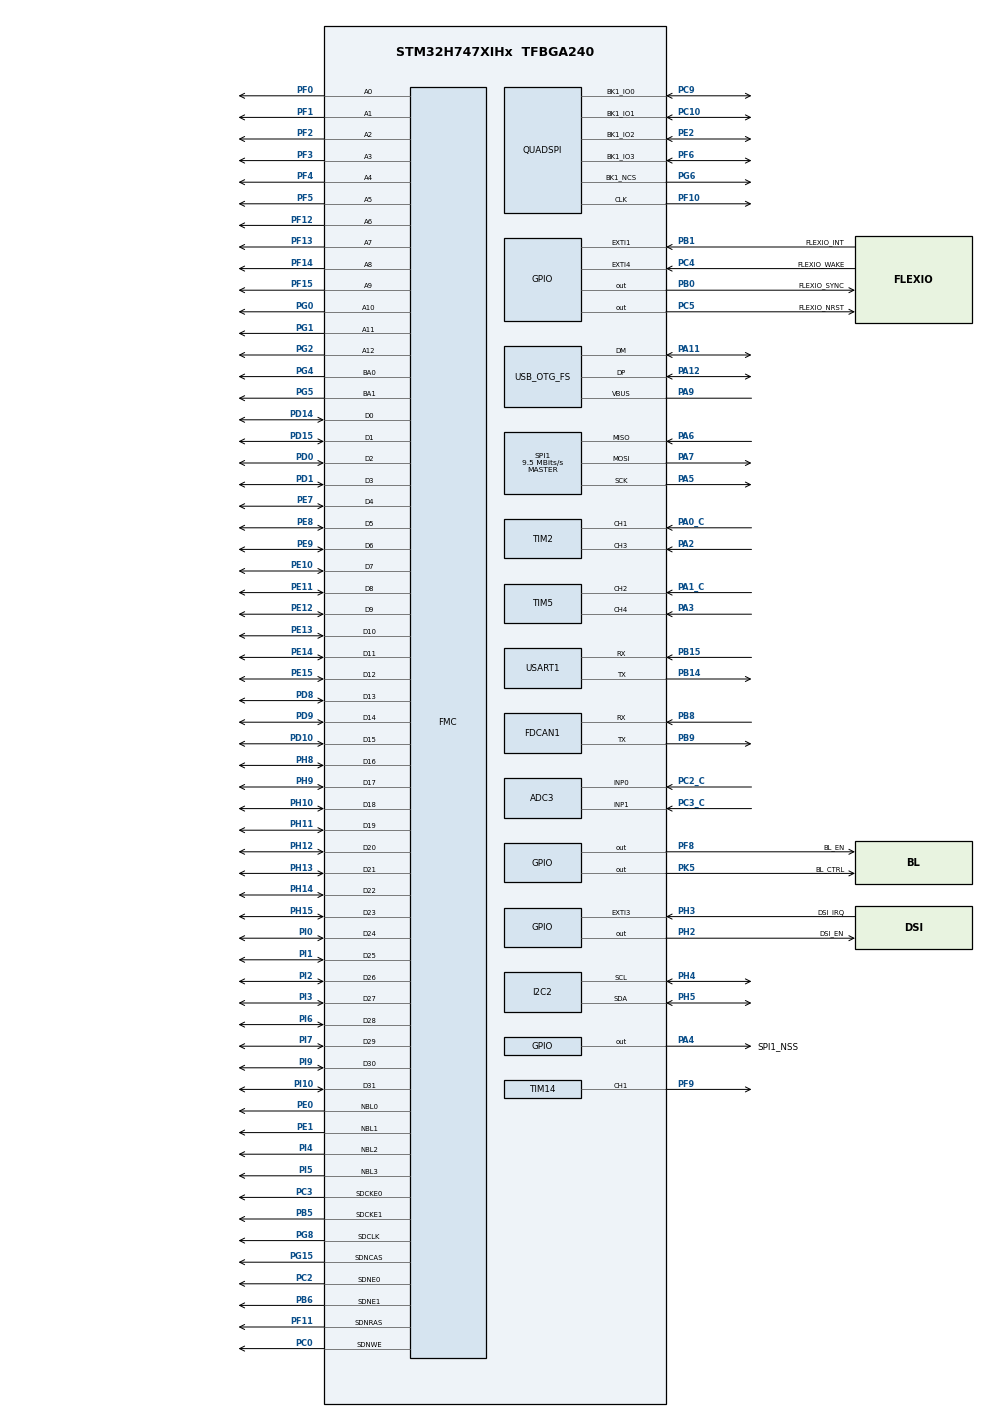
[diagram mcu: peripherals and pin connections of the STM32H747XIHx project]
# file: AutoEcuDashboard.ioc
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ADC3.AWD2FilteringConfig-Analog\ Watchdog\ 2=ADC3_AWD_FILTERING_NONE
ADC3.Channel-0\#ChannelRegularConversion=ADC_CHANNEL_0
ADC3.Channel-1\#ChannelRegularConversion=ADC_CHANNEL_1
ADC3.ContinuousConvMode=DISABLE
ADC3.EOCSelection=ADC_EOC_SEQ_CONV
ADC3.ExternalTrigConv=ADC_EXTERNALTRIG_T8_TRGO
ADC3.NbrOfConversion=2
ADC3.NbrOfConversionFlag=1
ADC3.OffsetNumber-0\#ChannelRegularConversion=ADC_OFFSET_NONE
ADC3.OffsetNumber-1\#ChannelRegularConversion=ADC_OFFSET_NONE
ADC3.OffsetSignedSaturation-0\#ChannelRegularConversion=DISABLE
ADC3.OffsetSignedSaturation-1\#ChannelRegularConversion=DISABLE
ADC3.Rank-0\#ChannelRegularConversion=1
ADC3.Rank-1\#ChannelRegularConversion=2
ADC3.SamplingTime-0\#ChannelRegularConversion=ADC_SAMPLETIME_64CYCLES_5
ADC3.SamplingTime-1\#ChannelRegularConversion=ADC_SAMPLETIME_64CYCLES_5
Bdma.ADC3.0.Direction=DMA_PERIPH_TO_MEMORY
Bdma.ADC3.0.EventEnable=DISABLE
Bdma.ADC3.0.Instance=BDMA_Channel0
Bdma.ADC3.0.MemDataAlignment=DMA_MDATAALIGN_HALFWORD
Bdma.ADC3.0.MemInc=DMA_MINC_ENABLE
Bdma.ADC3.0.Mode=DMA_CIRCULAR
Bdma.ADC3.0.PeriphDataAlignment=DMA_PDATAALIGN_HALFWORD
Bdma.ADC3.0.PeriphInc=DMA_PINC_DISABLE
Bdma.ADC3.0.Polarity=HAL_DMAMUX_REQ_GEN_RISING
Bdma.ADC3.0.Priority=DMA_PRIORITY_LOW
Bdma.ADC3.0.RequestNumber=1
Bdma.ADC3.0.SignalID=NONE
Bdma.ADC3.0.SyncEnable=DISABLE
Bdma.ADC3.0.SyncPolarity=HAL_DMAMUX_SYNC_NO_EVENT
Bdma.ADC3.0.SyncRequestNumber=1
Bdma.ADC3.0.SyncSignalID=NONE
Bdma.Request0=ADC3
Bdma.RequestsNb=1
CORTEX_M7.AccessPermission_Spec=MPU_REGION_PRIV_RW
CORTEX_M7.BaseAddress_Spec=0xC0000000
CORTEX_M7.CPU_DCache=Enabled
CORTEX_M7.CPU_ICache=Enabled
CORTEX_M7.DisableExec_Spec=MPU_INSTRUCTION_ACCESS_DISABLE
CORTEX_M7.Enable_Spec=MPU_REGION_ENABLE
CORTEX_M7.IsCacheable_Spec=MPU_ACCESS_CACHEABLE
CORTEX_M7.IsShareable_Spec=MPU_ACCESS_NOT_SHAREABLE
CORTEX_M7.Size_Spec=MPU_REGION_SIZE_64MB
CORTEX_M7.SubRegionDisable_Spec=0
CORTEX_M7.default_mode_Activation=1
CortexM4.IPs=CORTEX_M4\:I,FATFS_M4\:I,FREERTOS_M4\:I,IWDG2\:I,OPENAMP_M4\:I,PDM2PCM_M4\:I,PWR,RCC,RESMGR_UTILITY,SYS_M4\:I,USB_DEVICE_M4\:I,USB_HOST_M4\:I,VREFBUF,WWDG2\:I,GPIO,DMA,BDMA,MDMA,NVIC2\:I,DEBUG
CortexM7.IPs=CORTEX_M7\:I,FATFS_M7\:I,FREERTOS_M7\:I,IWDG1\:I,OPENAMP_M7\:I,PDM2PCM_M7\:I,PWR\:I,RCC\:I,RESMGR_UTILITY\:I,SYS\:I,USB_DEVICE_M7\:I,USB_HOST_M7\:I,VREFBUF\:I,WWDG1\:I,GPIO\:I,DMA\:I,BDMA\:I,MDMA\:I,NVIC1\:I,FMC\:I,DSIHOST\:I,LTDC\:I,CRC\:I,DMA2D\:I,JPEG\:I,DEBUG\:I,QUADSPI\:I,USB_OTG_FS\:I,USART1\:I,FDCAN1\:I,I2C2\:I,TIM2\:I,TIM5\:I,ADC3\:I,SPI1\:I,TIM14\:I,TIM8\:I,STMicroelectronics.X-CUBE-TOUCHGFX.4.25.0_M7\:I,TIM17\:I
CortexM7.Pins=PK5,PF8,PH2,PH3,PC4,PB1,PA4,PC5,PB0
DSIHOST.HorizontalBackPorch=148
DSIHOST.HorizontalLine=2200
DSIHOST.HorizontalSyncActive=44
DSIHOST.NumberOfLanes=DSI_TWO_DATA_LANES
DSI_CKN.Mode=DSIHost_Video
DSI_CKN.PinAttribute=CortexM7
DSI_CKN.Signal=DSIHOST_CKN
DSI_CKP.Mode=DSIHost_Video
DSI_CKP.PinAttribute=CortexM7
DSI_CKP.Signal=DSIHOST_CKP
DSI_D0N.Mode=DSIHost_Video
DSI_D0N.PinAttribute=CortexM7
DSI_D0N.Signal=DSIHOST_D0N
DSI_D0P.Mode=DSIHost_Video
DSI_D0P.PinAttribute=CortexM7
DSI_D0P.Signal=DSIHOST_D0P
DSI_D1N.Mode=DSIHost_Video
DSI_D1N.PinAttribute=CortexM7
DSI_D1N.Signal=DSIHOST_D1N
DSI_D1P.Mode=DSIHost_Video
DSI_D1P.PinAttribute=CortexM7
DSI_D1P.Signal=DSIHOST_D1P
Dma.Request0=SPI1_RX
Dma.Request1=SPI1_TX
Dma.Request2=USART1_RX
Dma.Request3=USART1_TX
Dma.SPI1_RX.0.Direction=DMA_PERIPH_TO_MEMORY
Dma.SPI1_RX.0.EventEnable=DISABLE
Dma.SPI1_RX.0.FIFOMode=DMA_FIFOMODE_DISABLE
Dma.SPI1_RX.0.Instance=DMA1_Stream0
Dma.SPI1_RX.0.MemDataAlignment=DMA_MDATAALIGN_BYTE
Dma.SPI1_RX.0.MemInc=DMA_MINC_ENABLE
Dma.SPI1_RX.0.Mode=DMA_NORMAL
Dma.SPI1_RX.0.PeriphDataAlignment=DMA_PDATAALIGN_BYTE
Dma.SPI1_RX.0.PeriphInc=DMA_PINC_DISABLE
Dma.SPI1_RX.0.Polarity=HAL_DMAMUX_REQ_GEN_RISING
Dma.SPI1_RX.0.Priority=DMA_PRIORITY_LOW
Dma.SPI1_RX.0.RequestNumber=1
Dma.SPI1_RX.0.SignalID=NONE
Dma.SPI1_RX.0.SyncEnable=DISABLE
Dma.SPI1_RX.0.SyncPolarity=HAL_DMAMUX_SYNC_NO_EVENT
Dma.SPI1_RX.0.SyncRequestNumber=1
Dma.SPI1_RX.0.SyncSignalID=NONE
Dma.SPI1_TX.1.Direction=DMA_MEMORY_TO_PERIPH
Dma.SPI1_TX.1.EventEnable=DISABLE
Dma.SPI1_TX.1.FIFOMode=DMA_FIFOMODE_DISABLE
Dma.SPI1_TX.1.Instance=DMA1_Stream1
Dma.SPI1_TX.1.MemDataAlignment=DMA_MDATAALIGN_BYTE
Dma.SPI1_TX.1.MemInc=DMA_MINC_ENABLE
Dma.SPI1_TX.1.Mode=DMA_NORMAL
Dma.SPI1_TX.1.PeriphDataAlignment=DMA_PDATAALIGN_BYTE
Dma.SPI1_TX.1.PeriphInc=DMA_PINC_DISABLE
Dma.SPI1_TX.1.Polarity=HAL_DMAMUX_REQ_GEN_RISING
Dma.SPI1_TX.1.Priority=DMA_PRIORITY_LOW
Dma.SPI1_TX.1.RequestNumber=1
Dma.SPI1_TX.1.SignalID=NONE
Dma.SPI1_TX.1.SyncEnable=DISABLE
Dma.SPI1_TX.1.SyncPolarity=HAL_DMAMUX_SYNC_NO_EVENT
Dma.SPI1_TX.1.SyncRequestNumber=1
Dma.SPI1_TX.1.SyncSignalID=NONE
Dma.USART1_RX.2.Direction=DMA_PERIPH_TO_MEMORY
Dma.USART1_RX.2.EventEnable=DISABLE
Dma.USART1_RX.2.FIFOMode=DMA_FIFOMODE_DISABLE
Dma.USART1_RX.2.Instance=DMA1_Stream2
Dma.USART1_RX.2.MemDataAlignment=DMA_MDATAALIGN_BYTE
Dma.USART1_RX.2.MemInc=DMA_MINC_ENABLE
Dma.USART1_RX.2.Mode=DMA_NORMAL
Dma.USART1_RX.2.PeriphDataAlignment=DMA_PDATAALIGN_BYTE
Dma.USART1_RX.2.PeriphInc=DMA_PINC_DISABLE
Dma.USART1_RX.2.Polarity=HAL_DMAMUX_REQ_GEN_RISING
Dma.USART1_RX.2.Priority=DMA_PRIORITY_LOW
Dma.USART1_RX.2.RequestNumber=1
Dma.USART1_RX.2.SignalID=NONE
Dma.USART1_RX.2.SyncEnable=DISABLE
Dma.USART1_RX.2.SyncPolarity=HAL_DMAMUX_SYNC_NO_EVENT
Dma.USART1_RX.2.SyncRequestNumber=1
Dma.USART1_RX.2.SyncSignalID=NONE
Dma.USART1_TX.3.Direction=DMA_MEMORY_TO_PERIPH
Dma.USART1_TX.3.EventEnable=DISABLE
Dma.USART1_TX.3.FIFOMode=DMA_FIFOMODE_DISABLE
Dma.USART1_TX.3.Instance=DMA1_Stream3
Dma.USART1_TX.3.MemDataAlignment=DMA_MDATAALIGN_BYTE
Dma.USART1_TX.3.MemInc=DMA_MINC_ENABLE
Dma.USART1_TX.3.Mode=DMA_NORMAL
Dma.USART1_TX.3.PeriphDataAlignment=DMA_PDATAALIGN_BYTE
Dma.USART1_TX.3.PeriphInc=DMA_PINC_DISABLE
Dma.USART1_TX.3.Polarity=HAL_DMAMUX_REQ_GEN_RISING
Dma.USART1_TX.3.Priority=DMA_PRIORITY_LOW
Dma.USART1_TX.3.RequestNumber=1
Dma.USART1_TX.3.SignalID=NONE
Dma.USART1_TX.3.SyncEnable=DISABLE
Dma.USART1_TX.3.SyncPolarity=HAL_DMAMUX_SYNC_NO_EVENT
Dma.USART1_TX.3.SyncRequestNumber=1
Dma.USART1_TX.3.SyncSignalID=NONE
FDCAN1.AutoRetransmission=ENABLE
FDCAN1.CalculateBaudRateNominal=500000
FDCAN1.CalculateTimeBitNominal=2000
FDCAN1.CalculateTimeQuantumNominal=250.0
FDCAN1.NominalPrescaler=12
FDCAN1.NominalTimeSeg1=4
FDCAN1.NominalTimeSeg2=3
FDCAN1.RxBuffersNbr=64
FDCAN1.RxFifo0ElmtsNbr=64
FDCAN1.RxFifo1ElmtsNbr=64
FDCAN1.TxBuffersNbr=32
FDCAN1.TxEventsNbr=32
FREERTOS_M7.Tasks01=defaultTask,24,2048,StartDefaultTask,Default,NULL,Dynamic,NULL,NULL
FREERTOS_M7.configENABLE_FPU=1
FREERTOS_M7.configMINIMAL_STACK_SIZE=2048
FREERTOS_M7.configTOTAL_HEAP_SIZE=32768
FREERTOS_M7.configUSE_IDLE_HOOK=1
FREERTOS_M7.configUSE_NEWLIB_REENTRANT=1
FREERTOS_M7.configUSE_TICK_HOOK=1
I2C2.Timing=0x307075B1
LTDC.ActiveH=720
LTDC.ActiveW=1920
LTDC.Alpha_L0=255
LTDC.Blue=0
LTDC.FBStartAdress_L0=0xC0000000
LTDC.Green=0
LTDC.HBP=148
LTDC.HFP=88
LTDC.HSPolarity=LTDC_HSPOLARITY_AH
LTDC.HSync=44
LTDC.ImageHeight_L0=720
LTDC.ImageWidth_L0=1920
LTDC.Layers=0
LTDC.PixelFormat_L0=LTDC_PIXEL_FORMAT_RGB888
LTDC.VBP=36
LTDC.VFP=4
LTDC.VSPolarity=LTDC_VSPOLARITY_AH
LTDC.VSync=5
LTDC.WindowX1_L0=1920
LTDC.WindowY1_L0=720
Mcu.Family=STM32H7
Mcu.Name=STM32H747XIHx
Mcu.Package=TFBGA240
NVIC1.ADC3_IRQn=true\:5\:0\:false\:false\:true\:true\:true\:true\:true
NVIC1.BDMA_Channel0_IRQn=true\:5\:0\:false\:false\:true\:true\:false\:true\:true
NVIC1.DMA1_Stream0_IRQn=true\:5\:0\:false\:false\:true\:true\:false\:true\:true
NVIC1.DMA1_Stream1_IRQn=true\:5\:0\:false\:false\:true\:true\:false\:true\:true
NVIC1.DMA1_Stream2_IRQn=true\:5\:0\:false\:false\:true\:true\:false\:true\:true
NVIC1.DMA1_Stream3_IRQn=true\:5\:0\:false\:false\:true\:true\:false\:true\:true
NVIC1.DMA2D_IRQn=true\:5\:0\:false\:false\:true\:true\:true\:true\:true
NVIC1.DSI_IRQn=true\:5\:0\:false\:false\:true\:true\:true\:true\:true
NVIC1.FMC_IRQn=true\:5\:0\:false\:false\:true\:true\:true\:true\:true
NVIC1.I2C2_ER_IRQn=true\:5\:0\:false\:false\:true\:true\:true\:true\:true
NVIC1.I2C2_EV_IRQn=true\:5\:0\:false\:false\:true\:true\:true\:true\:true
NVIC1.JPEG_IRQn=true\:5\:0\:false\:false\:true\:true\:true\:true\:true
NVIC1.LTDC_ER_IRQn=true\:5\:0\:false\:false\:true\:true\:true\:true\:true
NVIC1.LTDC_IRQn=true\:5\:0\:false\:false\:true\:true\:true\:true\:true
NVIC1.OTG_FS_EP1_IN_IRQn=true\:5\:0\:false\:false\:true\:true\:true\:true\:true
NVIC1.OTG_FS_EP1_OUT_IRQn=true\:5\:0\:false\:false\:true\:true\:true\:true\:true
NVIC1.OTG_FS_IRQn=true\:5\:0\:false\:false\:true\:true\:true\:true\:true
NVIC1.PriorityGroup=NVIC_PRIORITYGROUP_4
NVIC1.QUADSPI_IRQn=true\:5\:0\:false\:false\:true\:true\:true\:true\:true
NVIC1.SPI1_IRQn=true\:5\:0\:false\:false\:true\:true\:false\:true\:true
NVIC1.TIM17_IRQn=true\:15\:0\:false\:false\:true\:false\:true\:true\:true
NVIC1.TimeBase=TIM17_IRQn
NVIC1.TimeBaseIP=TIM17
NVIC2.PriorityGroup=NVIC_PRIORITYGROUP_4
PA0_C.PinAttribute=CortexM7
PA0_C.Signal=S_TIM2_CH1_ETR
PA11.GPIO_PuPd=GPIO_PULLUP
PA11.GPIO_Speed=GPIO_SPEED_FREQ_VERY_HIGH
PA11.Mode=Device_Only
PA11.PinAttribute=CortexM7
PA11.Signal=USB_OTG_FS_DM
PA12.GPIO_PuPd=GPIO_PULLUP
PA12.GPIO_Speed=GPIO_SPEED_FREQ_VERY_HIGH
PA12.Mode=Device_Only
PA12.PinAttribute=CortexM7
PA12.Signal=USB_OTG_FS_DP
PA13\ (JTMS/SWDIO).Mode=Trace_Asynchronous_SW
PA13\ (JTMS/SWDIO).PinAttribute=CortexM7
PA13\ (JTMS/SWDIO).Signal=DEBUG_JTMS-SWDIO
PA14\ (JTCK/SWCLK).Mode=Trace_Asynchronous_SW
PA14\ (JTCK/SWCLK).PinAttribute=CortexM7
PA14\ (JTCK/SWCLK).Signal=DEBUG_JTCK-SWCLK
PA1_C.PinAttribute=CortexM7
PA1_C.Signal=S_TIM5_CH2
PA2.GPIO_Speed=GPIO_SPEED_FREQ_VERY_HIGH
PA2.PinAttribute=CortexM7
PA2.Signal=S_TIM2_CH3
PA3.PinAttribute=CortexM7
PA3.Signal=S_TIM5_CH4
PA4.GPIO_Label=SPI1_NSS
PA4.GPIO_Speed=GPIO_SPEED_FREQ_VERY_HIGH
PA4.PinAttribute=CortexM7
PA4.PinState=GPIO_PIN_SET
PA4.Signal=GPIO_Output
PA5.Mode=Full_Duplex_Master
PA5.PinAttribute=CortexM7
PA5.Signal=SPI1_SCK
PA6.Mode=Full_Duplex_Master
PA6.PinAttribute=CortexM7
PA6.Signal=SPI1_MISO
PA7.Mode=Full_Duplex_Master
PA7.PinAttribute=CortexM7
PA7.Signal=SPI1_MOSI
PA9.Mode=Activate_VBUS
PA9.PinAttribute=CortexM7
PA9.Signal=USB_OTG_FS_VBUS
PB0.GPIO_Label=FLEXIO_SYNC
PB0.GPIO_Speed=GPIO_SPEED_FREQ_VERY_HIGH
PB0.PinAttribute=CortexM7
PB0.Signal=GPIO_Output
PB1.GPIO_Label=FLEXIO_INT
PB1.GPIO_ModeDefaultEXTI=GPIO_MODE_IT_RISING
PB1.GPIO_PuPd=GPIO_PULLDOWN
PB1.PinAttribute=CortexM7
PB1.Signal=GPXTI1
PB14.Mode=Asynchronous
PB14.PinAttribute=CortexM7
PB14.Signal=USART1_TX
PB15.Mode=Asynchronous
PB15.PinAttribute=CortexM7
PB15.Signal=USART1_RX
PB3\ (JTDO/TRACESWO).Mode=Trace_Asynchronous_SW
PB3\ (JTDO/TRACESWO).PinAttribute=CortexM7
PB3\ (JTDO/TRACESWO).Signal=DEBUG_JTDO-SWO
PB5.GPIO_PuPd=GPIO_PULLUP
PB5.GPIO_Speed_High_Default=GPIO_SPEED_FREQ_VERY_HIGH
PB5.Mode=SdramChipSelect2_2
PB5.PinAttribute=CortexM7
PB5.Signal=FMC_SDCKE1
PB6.GPIO_PuPd=GPIO_PULLUP
PB6.GPIO_Speed_High_Default=GPIO_SPEED_FREQ_VERY_HIGH
PB6.Mode=SdramChipSelect2_2
PB6.PinAttribute=CortexM7
PB6.Signal=FMC_SDNE1
PB8.Mode=FDCAN_Activate
PB8.PinAttribute=CortexM7
PB8.Signal=FDCAN1_RX
PB9.Mode=FDCAN_Activate
PB9.PinAttribute=CortexM7
PB9.Signal=FDCAN1_TX
PC0.GPIO_PuPd=GPIO_PULLUP
PC0.GPIO_Speed_High_Default=GPIO_SPEED_FREQ_VERY_HIGH
PC0.PinAttribute=CortexM7
PC0.Signal=FMC_SDNWE
PC10.GPIO_PuPd=GPIO_PULLUP
PC10.GPIO_Speed=GPIO_SPEED_FREQ_VERY_HIGH
PC10.Mode=Single Bank 1
PC10.PinAttribute=CortexM7
PC10.Signal=QUADSPI_BK1_IO1
PC2.GPIO_PuPd=GPIO_PULLUP
PC2.GPIO_Speed_High_Default=GPIO_SPEED_FREQ_VERY_HIGH
PC2.Mode=SdramChipSelect1_1
PC2.PinAttribute=CortexM7
PC2.Signal=FMC_SDNE0
PC2_C.Mode=IN0-Single-Ended
PC2_C.PinAttribute=CortexM7
PC2_C.Signal=ADC3_INP0
PC3.GPIO_PuPd=GPIO_PULLUP
PC3.GPIO_Speed_High_Default=GPIO_SPEED_FREQ_VERY_HIGH
PC3.Mode=SdramChipSelect1_1
PC3.PinAttribute=CortexM7
PC3.Signal=FMC_SDCKE0
PC3_C.Mode=IN1-Single-Ended
PC3_C.PinAttribute=CortexM7
PC3_C.Signal=ADC3_INP1
PC4.GPIO_Label=FLEXIO_WAKE
PC4.PinAttribute=CortexM7
PC4.Signal=GPXTI4
PC5.GPIO_Label=FLEXIO_NRST
PC5.PinAttribute=CortexM7
PC5.Signal=GPIO_Output
PC9.GPIO_PuPd=GPIO_PULLUP
PC9.GPIO_Speed=GPIO_SPEED_FREQ_VERY_HIGH
PC9.Mode=Single Bank 1
PC9.PinAttribute=CortexM7
PC9.Signal=QUADSPI_BK1_IO0
PD0.GPIO_PuPd=GPIO_PULLUP
PD0.GPIO_Speed_High_Default=GPIO_SPEED_FREQ_VERY_HIGH
PD0.PinAttribute=CortexM7
PD0.Signal=FMC_D2_DA2
PD1.GPIO_PuPd=GPIO_PULLUP
PD1.GPIO_Speed_High_Default=GPIO_SPEED_FREQ_VERY_HIGH
PD1.PinAttribute=CortexM7
PD1.Signal=FMC_D3_DA3
PD10.GPIO_PuPd=GPIO_PULLUP
PD10.GPIO_Speed_High_Default=GPIO_SPEED_FREQ_VERY_HIGH
PD10.PinAttribute=CortexM7
PD10.Signal=FMC_D15_DA15
PD14.GPIO_PuPd=GPIO_PULLUP
PD14.GPIO_Speed_High_Default=GPIO_SPEED_FREQ_VERY_HIGH
PD14.PinAttribute=CortexM7
PD14.Signal=FMC_D0_DA0
PD15.GPIO_PuPd=GPIO_PULLUP
PD15.GPIO_Speed_High_Default=GPIO_SPEED_FREQ_VERY_HIGH
PD15.PinAttribute=CortexM7
PD15.Signal=FMC_D1_DA1
PD8.GPIO_PuPd=GPIO_PULLUP
PD8.GPIO_Speed_High_Default=GPIO_SPEED_FREQ_VERY_HIGH
PD8.PinAttribute=CortexM7
PD8.Signal=FMC_D13_DA13
PD9.GPIO_PuPd=GPIO_PULLUP
PD9.GPIO_Speed_High_Default=GPIO_SPEED_FREQ_VERY_HIGH
PD9.PinAttribute=CortexM7
PD9.Signal=FMC_D14_DA14
PE0.GPIO_PuPd=GPIO_PULLUP
PE0.GPIO_Speed_High_Default=GPIO_SPEED_FREQ_VERY_HIGH
PE0.PinAttribute=CortexM7
PE0.Signal=FMC_NBL0
PE1.GPIO_PuPd=GPIO_PULLUP
PE1.GPIO_Speed_High_Default=GPIO_SPEED_FREQ_VERY_HIGH
PE1.PinAttribute=CortexM7
PE1.Signal=FMC_NBL1
PE10.GPIO_PuPd=GPIO_PULLUP
PE10.GPIO_Speed_High_Default=GPIO_SPEED_FREQ_VERY_HIGH
PE10.PinAttribute=CortexM7
PE10.Signal=FMC_D7_DA7
PE11.GPIO_PuPd=GPIO_PULLUP
PE11.GPIO_Speed_High_Default=GPIO_SPEED_FREQ_VERY_HIGH
PE11.PinAttribute=CortexM7
PE11.Signal=FMC_D8_DA8
PE12.GPIO_PuPd=GPIO_PULLUP
PE12.GPIO_Speed_High_Default=GPIO_SPEED_FREQ_VERY_HIGH
PE12.PinAttribute=CortexM7
PE12.Signal=FMC_D9_DA9
PE13.GPIO_PuPd=GPIO_PULLUP
PE13.GPIO_Speed_High_Default=GPIO_SPEED_FREQ_VERY_HIGH
PE13.PinAttribute=CortexM7
PE13.Signal=FMC_D10_DA10
PE14.GPIO_PuPd=GPIO_PULLUP
PE14.GPIO_Speed_High_Default=GPIO_SPEED_FREQ_VERY_HIGH
PE14.PinAttribute=CortexM7
PE14.Signal=FMC_D11_DA11
PE15.GPIO_PuPd=GPIO_PULLUP
PE15.GPIO_Speed_High_Default=GPIO_SPEED_FREQ_VERY_HIGH
PE15.PinAttribute=CortexM7
PE15.Signal=FMC_D12_DA12
PE2.GPIO_PuPd=GPIO_PULLUP
PE2.GPIO_Speed=GPIO_SPEED_FREQ_VERY_HIGH
PE2.Mode=Single Bank 1
PE2.PinAttribute=CortexM7
PE2.Signal=QUADSPI_BK1_IO2
PE7.GPIO_PuPd=GPIO_PULLUP
PE7.GPIO_Speed_High_Default=GPIO_SPEED_FREQ_VERY_HIGH
PE7.PinAttribute=CortexM7
PE7.Signal=FMC_D4_DA4
PE8.GPIO_PuPd=GPIO_PULLUP
PE8.GPIO_Speed_High_Default=GPIO_SPEED_FREQ_VERY_HIGH
PE8.PinAttribute=CortexM7
PE8.Signal=FMC_D5_DA5
PE9.GPIO_PuPd=GPIO_PULLUP
PE9.GPIO_Speed_High_Default=GPIO_SPEED_FREQ_VERY_HIGH
PE9.PinAttribute=CortexM7
PE9.Signal=FMC_D6_DA6
PF0.GPIO_PuPd=GPIO_PULLUP
PF0.GPIO_Speed_High_Default=GPIO_SPEED_FREQ_VERY_HIGH
PF0.PinAttribute=CortexM7
PF0.Signal=FMC_A0
PF1.GPIO_PuPd=GPIO_PULLUP
PF1.GPIO_Speed_High_Default=GPIO_SPEED_FREQ_VERY_HIGH
PF1.PinAttribute=CortexM7
PF1.Signal=FMC_A1
PF10.GPIO_PuPd=GPIO_PULLUP
PF10.GPIO_Speed=GPIO_SPEED_FREQ_VERY_HIGH
PF10.Mode=Single Bank 1
PF10.PinAttribute=CortexM7
PF10.Signal=QUADSPI_CLK
PF11.GPIO_PuPd=GPIO_PULLUP
PF11.GPIO_Speed_High_Default=GPIO_SPEED_FREQ_VERY_HIGH
PF11.PinAttribute=CortexM7
PF11.Signal=FMC_SDNRAS
PF12.GPIO_PuPd=GPIO_PULLUP
PF12.GPIO_Speed_High_Default=GPIO_SPEED_FREQ_VERY_HIGH
PF12.PinAttribute=CortexM7
PF12.Signal=FMC_A6
PF13.GPIO_PuPd=GPIO_PULLUP
PF13.GPIO_Speed_High_Default=GPIO_SPEED_FREQ_VERY_HIGH
PF13.PinAttribute=CortexM7
PF13.Signal=FMC_A7
PF14.GPIO_PuPd=GPIO_PULLUP
PF14.GPIO_Speed_High_Default=GPIO_SPEED_FREQ_VERY_HIGH
PF14.PinAttribute=CortexM7
PF14.Signal=FMC_A8
PF15.GPIO_PuPd=GPIO_PULLUP
PF15.GPIO_Speed_High_Default=GPIO_SPEED_FREQ_VERY_HIGH
PF15.PinAttribute=CortexM7
PF15.Signal=FMC_A9
PF2.GPIO_PuPd=GPIO_PULLUP
PF2.GPIO_Speed_High_Default=GPIO_SPEED_FREQ_VERY_HIGH
PF2.PinAttribute=CortexM7
PF2.Signal=FMC_A2
PF3.GPIO_PuPd=GPIO_PULLUP
PF3.GPIO_Speed_High_Default=GPIO_SPEED_FREQ_VERY_HIGH
PF3.PinAttribute=CortexM7
PF3.Signal=FMC_A3
PF4.GPIO_PuPd=GPIO_PULLUP
PF4.GPIO_Speed_High_Default=GPIO_SPEED_FREQ_VERY_HIGH
PF4.PinAttribute=CortexM7
PF4.Signal=FMC_A4
PF5.GPIO_PuPd=GPIO_PULLUP
PF5.GPIO_Speed_High_Default=GPIO_SPEED_FREQ_VERY_HIGH
PF5.PinAttribute=CortexM7
PF5.Signal=FMC_A5
PF6.GPIO_PuPd=GPIO_PULLUP
PF6.GPIO_Speed=GPIO_SPEED_FREQ_VERY_HIGH
PF6.Mode=Single Bank 1
PF6.PinAttribute=CortexM7
PF6.Signal=QUADSPI_BK1_IO3
PF8.GPIO_Label=BL_EN
PF8.PinAttribute=CortexM7
PF8.Signal=GPIO_Output
PF9.GPIO_Speed=GPIO_SPEED_FREQ_VERY_HIGH
PF9.PinAttribute=CortexM7
PF9.Signal=S_TIM14_CH1
PG0.GPIO_PuPd=GPIO_PULLUP
PG0.GPIO_Speed_High_Default=GPIO_SPEED_FREQ_VERY_HIGH
PG0.PinAttribute=CortexM7
PG0.Signal=FMC_A10
PG1.GPIO_PuPd=GPIO_PULLUP
PG1.GPIO_Speed_High_Default=GPIO_SPEED_FREQ_VERY_HIGH
PG1.PinAttribute=CortexM7
PG1.Signal=FMC_A11
PG15.GPIO_PuPd=GPIO_PULLUP
PG15.GPIO_Speed_High_Default=GPIO_SPEED_FREQ_VERY_HIGH
PG15.PinAttribute=CortexM7
PG15.Signal=FMC_SDNCAS
PG2.GPIO_PuPd=GPIO_PULLUP
PG2.GPIO_Speed_High_Default=GPIO_SPEED_FREQ_VERY_HIGH
PG2.PinAttribute=CortexM7
PG2.Signal=FMC_A12
PG4.GPIO_PuPd=GPIO_PULLUP
PG4.GPIO_Speed_High_Default=GPIO_SPEED_FREQ_VERY_HIGH
PG4.PinAttribute=CortexM7
PG4.Signal=FMC_A14_BA0
PG5.GPIO_PuPd=GPIO_PULLUP
PG5.GPIO_Speed_High_Default=GPIO_SPEED_FREQ_VERY_HIGH
PG5.PinAttribute=CortexM7
PG5.Signal=FMC_A15_BA1
PG6.GPIO_PuPd=GPIO_PULLUP
PG6.GPIO_Speed=GPIO_SPEED_FREQ_VERY_HIGH
PG6.Mode=Single Bank 1
PG6.PinAttribute=CortexM7
PG6.Signal=QUADSPI_BK1_NCS
PG8.GPIO_PuPd=GPIO_PULLUP
PG8.GPIO_Speed_High_Default=GPIO_SPEED_FREQ_VERY_HIGH
PG8.PinAttribute=CortexM7
PG8.Signal=FMC_SDCLK
PH0-OSC_IN\ (PH0).Mode=HSE-External-Clock-Source
PH0-OSC_IN\ (PH0).PinAttribute=Free
PH0-OSC_IN\ (PH0).Signal=RCC_OSC_IN
PH10.GPIO_PuPd=GPIO_PULLUP
PH10.GPIO_Speed_High_Default=GPIO_SPEED_FREQ_VERY_HIGH
PH10.PinAttribute=CortexM7
PH10.Signal=FMC_D18
PH11.GPIO_PuPd=GPIO_PULLUP
PH11.GPIO_Speed_High_Default=GPIO_SPEED_FREQ_VERY_HIGH
PH11.PinAttribute=CortexM7
PH11.Signal=FMC_D19
PH12.GPIO_PuPd=GPIO_PULLUP
PH12.GPIO_Speed_High_Default=GPIO_SPEED_FREQ_VERY_HIGH
PH12.PinAttribute=CortexM7
PH12.Signal=FMC_D20
PH13.GPIO_PuPd=GPIO_PULLUP
PH13.GPIO_Speed_High_Default=GPIO_SPEED_FREQ_VERY_HIGH
PH13.PinAttribute=CortexM7
PH13.Signal=FMC_D21
PH14.GPIO_PuPd=GPIO_PULLUP
PH14.GPIO_Speed_High_Default=GPIO_SPEED_FREQ_VERY_HIGH
PH14.PinAttribute=CortexM7
PH14.Signal=FMC_D22
PH15.GPIO_PuPd=GPIO_PULLUP
PH15.GPIO_Speed_High_Default=GPIO_SPEED_FREQ_VERY_HIGH
PH15.PinAttribute=CortexM7
PH15.Signal=FMC_D23
PH2.GPIO_Label=DSI_EN
PH2.GPIO_Speed=GPIO_SPEED_FREQ_VERY_HIGH
PH2.PinAttribute=CortexM7
PH2.Signal=GPIO_Output
PH3.GPIO_Label=DSI_IRQ
PH3.GPIO_PuPd=GPIO_PULLDOWN
PH3.PinAttribute=CortexM7
PH3.Signal=GPXTI3
PH4.Mode=I2C
PH4.PinAttribute=CortexM7
PH4.Signal=I2C2_SCL
PH5.Mode=I2C
PH5.PinAttribute=CortexM7
PH5.Signal=I2C2_SDA
PH8.GPIO_PuPd=GPIO_PULLUP
PH8.GPIO_Speed_High_Default=GPIO_SPEED_FREQ_VERY_HIGH
PH8.PinAttribute=CortexM7
PH8.Signal=FMC_D16
PH9.GPIO_PuPd=GPIO_PULLUP
PH9.GPIO_Speed_High_Default=GPIO_SPEED_FREQ_VERY_HIGH
PH9.PinAttribute=CortexM7
PH9.Signal=FMC_D17
PI0.GPIO_PuPd=GPIO_PULLUP
PI0.GPIO_Speed_High_Default=GPIO_SPEED_FREQ_VERY_HIGH
PI0.PinAttribute=CortexM7
PI0.Signal=FMC_D24
PI1.GPIO_PuPd=GPIO_PULLUP
PI1.GPIO_Speed_High_Default=GPIO_SPEED_FREQ_VERY_HIGH
PI1.PinAttribute=CortexM7
PI1.Signal=FMC_D25
PI10.GPIO_PuPd=GPIO_PULLUP
PI10.GPIO_Speed_High_Default=GPIO_SPEED_FREQ_VERY_HIGH
PI10.PinAttribute=CortexM7
PI10.Signal=FMC_D31
PI2.GPIO_PuPd=GPIO_PULLUP
PI2.GPIO_Speed_High_Default=GPIO_SPEED_FREQ_VERY_HIGH
PI2.PinAttribute=CortexM7
PI2.Signal=FMC_D26
PI3.GPIO_PuPd=GPIO_PULLUP
PI3.GPIO_Speed_High_Default=GPIO_SPEED_FREQ_VERY_HIGH
PI3.PinAttribute=CortexM7
PI3.Signal=FMC_D27
PI4.GPIO_PuPd=GPIO_PULLUP
PI4.GPIO_Speed_High_Default=GPIO_SPEED_FREQ_VERY_HIGH
PI4.PinAttribute=CortexM7
PI4.Signal=FMC_NBL2
PI5.GPIO_PuPd=GPIO_PULLUP
PI5.GPIO_Speed_High_Default=GPIO_SPEED_FREQ_VERY_HIGH
PI5.PinAttribute=CortexM7
PI5.Signal=FMC_NBL3
PI6.GPIO_PuPd=GPIO_PULLUP
PI6.GPIO_Speed_High_Default=GPIO_SPEED_FREQ_VERY_HIGH
PI6.PinAttribute=CortexM7
PI6.Signal=FMC_D28
PI7.GPIO_PuPd=GPIO_PULLUP
PI7.GPIO_Speed_High_Default=GPIO_SPEED_FREQ_VERY_HIGH
PI7.PinAttribute=CortexM7
PI7.Signal=FMC_D29
PI9.GPIO_PuPd=GPIO_PULLUP
PI9.GPIO_Speed_High_Default=GPIO_SPEED_FREQ_VERY_HIGH
PI9.PinAttribute=CortexM7
PI9.Signal=FMC_D30
PK5.GPIO_Label=BL_CTRL
PK5.PinAttribute=CortexM7
PK5.Signal=GPIO_Output
ProjectManager.HeapSize=M4-0x2000,M7-0x2000
ProjectManager.StackSize=M4-0x4000,M7-0x4000
ProjectManager.TargetToolchain=STM32CubeIDE
QUADSPI.ClockPrescaler=0
QUADSPI.DeviceType=SPI_DEVICE_FLASH
QUADSPI.FifoThreshold=4
QUADSPI.FlashSize=22-1
RCC.ADCFreq_Value=38000000
RCC.APB1Freq_Value=120000000
RCC.APB2Freq_Value=120000000
RCC.APB3Freq_Value=120000000
RCC.APB4Freq_Value=120000000
RCC.CortexFreq_Value=480000000
RCC.D1PPRE=RCC_APB3_DIV2
RCC.D2PPRE1=RCC_APB1_DIV2
RCC.D2PPRE2=RCC_APB2_DIV2
RCC.D3PPRE=RCC_APB4_DIV2
RCC.DIVM1=4
RCC.DIVM2=4
RCC.DIVM3=4
RCC.DIVN1=480
RCC.DIVN2=266
RCC.DIVN3=375
RCC.DIVP2=14
RCC.DIVQ1=20
RCC.DIVQ3=12
RCC.DIVR1=4
RCC.DIVR3=9
RCC.EnbaleCSS=false
RCC.FMCCLockSelection=RCC_FMCCLKSOURCE_PLL2
RCC.HCLKFreq_Value=240000000
RCC.HPRE=RCC_HCLK_DIV2
RCC.HSE_VALUE=8000000
RCC.PLL1_VCI_Range-AdvancedSettings=RCC_PLL1VCIRANGE_0
RCC.PLL2FRACN=0
RCC.PLL2_VCO_SEL-AdvancedSettings=RCC_PLL2VCOWIDE
RCC.PLL3FRACN=0
RCC.PLL3_VCI_Range-AdvancedSettings=RCC_PLL3VCIRANGE_0
RCC.PLLDSINDIV=125
RCC.PLLFRACN=0
RCC.PLLSourceVirtual=RCC_PLLSOURCE_HSE
RCC.QSPICLockSelection=RCC_QSPICLKSOURCE_PLL
RCC.RCC_TIM_PRescaler_Selection=RCC_TIMPRES_DESACTIVATED
RCC.SPI123CLockSelection=RCC_SPI123CLKSOURCE_PLL2
RCC.SYSCLKFreq_VALUE=480000000
RCC.SYSCLKSource=RCC_SYSCLKSOURCE_PLLCLK
RCC.SupplySource=PWR_DIRECT_SMPS_SUPPLY
RCC.USBFreq_Value=48000000
SH.FMC_A0.0=FMC_A0,13b-sda1
SH.FMC_A0.1=FMC_A0,13b-sda2
SH.FMC_A1.0=FMC_A1,13b-sda1
SH.FMC_A1.1=FMC_A1,13b-sda2
SH.FMC_A10.0=FMC_A10,13b-sda1
SH.FMC_A10.1=FMC_A10,13b-sda2
SH.FMC_A11.0=FMC_A11,13b-sda1
SH.FMC_A11.1=FMC_A11,13b-sda2
SH.FMC_A12.0=FMC_A12,13b-sda1
SH.FMC_A12.1=FMC_A12,13b-sda2
SH.FMC_A14_BA0.0=FMC_BA0,FourSdramBanks1
SH.FMC_A14_BA0.1=FMC_BA0,FourSdramBanks2
SH.FMC_A15_BA1.0=FMC_BA1,FourSdramBanks1
SH.FMC_A15_BA1.1=FMC_BA1,FourSdramBanks2
SH.FMC_A2.0=FMC_A2,13b-sda1
SH.FMC_A2.1=FMC_A2,13b-sda2
SH.FMC_A3.0=FMC_A3,13b-sda1
SH.FMC_A3.1=FMC_A3,13b-sda2
SH.FMC_A4.0=FMC_A4,13b-sda1
SH.FMC_A4.1=FMC_A4,13b-sda2
SH.FMC_A5.0=FMC_A5,13b-sda1
SH.FMC_A5.1=FMC_A5,13b-sda2
SH.FMC_A6.0=FMC_A6,13b-sda1
SH.FMC_A6.1=FMC_A6,13b-sda2
SH.FMC_A7.0=FMC_A7,13b-sda1
SH.FMC_A7.1=FMC_A7,13b-sda2
SH.FMC_A8.0=FMC_A8,13b-sda1
SH.FMC_A8.1=FMC_A8,13b-sda2
SH.FMC_A9.0=FMC_A9,13b-sda1
SH.FMC_A9.1=FMC_A9,13b-sda2
SH.FMC_D0_DA0.0=FMC_D0,sd-32b-d1
SH.FMC_D0_DA0.1=FMC_D0,sd-32b-d2
SH.FMC_D10_DA10.0=FMC_D10,sd-32b-d1
SH.FMC_D10_DA10.1=FMC_D10,sd-32b-d2
SH.FMC_D11_DA11.0=FMC_D11,sd-32b-d1
SH.FMC_D11_DA11.1=FMC_D11,sd-32b-d2
SH.FMC_D12_DA12.0=FMC_D12,sd-32b-d1
SH.FMC_D12_DA12.1=FMC_D12,sd-32b-d2
SH.FMC_D13_DA13.0=FMC_D13,sd-32b-d1
SH.FMC_D13_DA13.1=FMC_D13,sd-32b-d2
SH.FMC_D14_DA14.0=FMC_D14,sd-32b-d1
SH.FMC_D14_DA14.1=FMC_D14,sd-32b-d2
SH.FMC_D15_DA15.0=FMC_D15,sd-32b-d1
SH.FMC_D15_DA15.1=FMC_D15,sd-32b-d2
SH.FMC_D16.0=FMC_D16,sd-32b-d1
SH.FMC_D16.1=FMC_D16,sd-32b-d2
SH.FMC_D17.0=FMC_D17,sd-32b-d1
SH.FMC_D17.1=FMC_D17,sd-32b-d2
SH.FMC_D18.0=FMC_D18,sd-32b-d1
SH.FMC_D18.1=FMC_D18,sd-32b-d2
SH.FMC_D19.0=FMC_D19,sd-32b-d1
SH.FMC_D19.1=FMC_D19,sd-32b-d2
SH.FMC_D1_DA1.0=FMC_D1,sd-32b-d1
SH.FMC_D1_DA1.1=FMC_D1,sd-32b-d2
SH.FMC_D20.0=FMC_D20,sd-32b-d1
SH.FMC_D20.1=FMC_D20,sd-32b-d2
SH.FMC_D21.0=FMC_D21,sd-32b-d1
SH.FMC_D21.1=FMC_D21,sd-32b-d2
SH.FMC_D22.0=FMC_D22,sd-32b-d1
SH.FMC_D22.1=FMC_D22,sd-32b-d2
SH.FMC_D23.0=FMC_D23,sd-32b-d1
SH.FMC_D23.1=FMC_D23,sd-32b-d2
SH.FMC_D24.0=FMC_D24,sd-32b-d1
SH.FMC_D24.1=FMC_D24,sd-32b-d2
SH.FMC_D25.0=FMC_D25,sd-32b-d1
SH.FMC_D25.1=FMC_D25,sd-32b-d2
SH.FMC_D26.0=FMC_D26,sd-32b-d1
SH.FMC_D26.1=FMC_D26,sd-32b-d2
SH.FMC_D27.0=FMC_D27,sd-32b-d1
SH.FMC_D27.1=FMC_D27,sd-32b-d2
SH.FMC_D28.0=FMC_D28,sd-32b-d1
SH.FMC_D28.1=FMC_D28,sd-32b-d2
SH.FMC_D29.0=FMC_D29,sd-32b-d1
SH.FMC_D29.1=FMC_D29,sd-32b-d2
SH.FMC_D2_DA2.0=FMC_D2,sd-32b-d1
SH.FMC_D2_DA2.1=FMC_D2,sd-32b-d2
SH.FMC_D30.0=FMC_D30,sd-32b-d1
SH.FMC_D30.1=FMC_D30,sd-32b-d2
SH.FMC_D31.0=FMC_D31,sd-32b-d1
SH.FMC_D31.1=FMC_D31,sd-32b-d2
SH.FMC_D3_DA3.0=FMC_D3,sd-32b-d1
SH.FMC_D3_DA3.1=FMC_D3,sd-32b-d2
SH.FMC_D4_DA4.0=FMC_D4,sd-32b-d1
SH.FMC_D4_DA4.1=FMC_D4,sd-32b-d2
SH.FMC_D5_DA5.0=FMC_D5,sd-32b-d1
SH.FMC_D5_DA5.1=FMC_D5,sd-32b-d2
SH.FMC_D6_DA6.0=FMC_D6,sd-32b-d1
SH.FMC_D6_DA6.1=FMC_D6,sd-32b-d2
SH.FMC_D7_DA7.0=FMC_D7,sd-32b-d1
SH.FMC_D7_DA7.1=FMC_D7,sd-32b-d2
SH.FMC_D8_DA8.0=FMC_D8,sd-32b-d1
SH.FMC_D8_DA8.1=FMC_D8,sd-32b-d2
SH.FMC_D9_DA9.0=FMC_D9,sd-32b-d1
SH.FMC_D9_DA9.1=FMC_D9,sd-32b-d2
SH.FMC_NBL0.0=FMC_NBL0,Sd4ByteEnable1
SH.FMC_NBL0.1=FMC_NBL0,Sd4ByteEnable2
SH.FMC_NBL1.0=FMC_NBL1,Sd4ByteEnable1
SH.FMC_NBL1.1=FMC_NBL1,Sd4ByteEnable2
SH.FMC_NBL2.0=FMC_NBL2,Sd4ByteEnable1
SH.FMC_NBL2.1=FMC_NBL2,Sd4ByteEnable2
SH.FMC_NBL3.0=FMC_NBL3,Sd4ByteEnable1
SH.FMC_NBL3.1=FMC_NBL3,Sd4ByteEnable2
SH.FMC_SDCLK.0=FMC_SDCLK,13b-sda1
SH.FMC_SDCLK.1=FMC_SDCLK,13b-sda2
SH.FMC_SDNCAS.0=FMC_SDNCAS,13b-sda1
SH.FMC_SDNCAS.1=FMC_SDNCAS,13b-sda2
SH.FMC_SDNRAS.0=FMC_SDNRAS,13b-sda1
SH.FMC_SDNRAS.1=FMC_SDNRAS,13b-sda2
SH.FMC_SDNWE.0=FMC_SDNWE,13b-sda1
SH.FMC_SDNWE.1=FMC_SDNWE,13b-sda2
SH.S_TIM14_CH1.0=TIM14_CH1,PWM Generation1 CH1
SH.S_TIM2_CH1_ETR.0=TIM2_CH1,Input_Capture1_from_TI1
SH.S_TIM2_CH3.0=TIM2_CH3,Input_Capture3_from_TI3
SH.S_TIM5_CH2.0=TIM5_CH2,Input_Capture2_from_TI2
SH.S_TIM5_CH4.0=TIM5_CH4,Input_Capture4_from_TI4
SPI1.BaudRatePrescaler=SPI_BAUDRATEPRESCALER_4
SPI1.CalculateBaudRate=9.5 MBits/s
SPI1.DataSize=SPI_DATASIZE_8BIT
SPI1.Direction=SPI_DIRECTION_2LINES
SPI1.Mode=SPI_MODE_MASTER
SPI1.VirtualType=VM_MASTER
STMicroelectronics.X-CUBE-TOUCHGFX.4.25.0_IsPackSelfContextualization=true
STMicroelectronics.X-CUBE-TOUCHGFX.4.25.0_M7.ApplicationCcGraphicsJjApplication=TouchGFXOoGenerator
STMicroelectronics.X-CUBE-TOUCHGFX.4.25.0_M7.tgfx_buffering_strategy=Double
STMicroelectronics.X-CUBE-TOUCHGFX.4.25.0_M7.tgfx_display_interface=disp_ltdc
STMicroelectronics.X-CUBE-TOUCHGFX.4.25.0_M7.tgfx_hardware_accelerator=dma_2d
STMicroelectronics.X-CUBE-TOUCHGFX.4.25.0_M7.tgfx_vector_rendering=Disabled
STMicroelectronics.X-CUBE-TOUCHGFX.4.25.0_M7.tgfx_video=Hardware
STMicroelectronics.X-CUBE-TOUCHGFX.4.25.0_M7.tgfx_video_height=720
STMicroelectronics.X-CUBE-TOUCHGFX.4.25.0_M7.tgfx_video_strategy=2
STMicroelectronics.X-CUBE-TOUCHGFX.4.25.0_M7.tgfx_video_width=1920
STMicroelectronics.X-CUBE-TOUCHGFX.4.25.0_M7.tgfx_vsync=vsync_ltdc
SYS.userName=SYS_M7
TIM14.Channel=TIM_CHANNEL_1
TIM14.OCPolarity_1=TIM_OCPOLARITY_HIGH
TIM14.Period=1000-1
TIM14.Prescaler=120-1
TIM2.Channel-Input_Capture1_from_TI1=TIM_CHANNEL_1
TIM2.Channel-Input_Capture2_from_TI1_63=TIM_CHANNEL_2
TIM2.Channel-Input_Capture3_from_TI3=TIM_CHANNEL_3
TIM2.Channel-Input_Capture4_from_TI3_63=TIM_CHANNEL_4
TIM5.Channel-Input_Capture1_from_TI2_63=TIM_CHANNEL_1
TIM5.Channel-Input_Capture2_from_TI2=TIM_CHANNEL_2
TIM5.Channel-Input_Capture3_from_TI4_63=TIM_CHANNEL_3
TIM5.Channel-Input_Capture4_from_TI4=TIM_CHANNEL_4
TIM8.Period=1000-1
TIM8.Prescaler=120-1
TIM8.TIM_MasterOutputTrigger=TIM_TRGO_UPDATE
USART1.VirtualMode-Asynchronous=VM_ASYNC
USB_DEVICE_M7.CLASS_NAME_FS=CDC
USB_DEVICE_M7.VirtualMode-CDC_FS=Cdc
USB_DEVICE_M7.VirtualModeFS=Cdc_FS
USB_OTG_FS.Sof_enable=ENABLE
USB_OTG_FS.VirtualMode=Device_Only
USB_OTG_FS.battery_charging_enable=DISABLE
USB_OTG_FS.dma_enable=ENABLE
USB_OTG_FS.use_dedicated_ep1=ENABLE
VP_CRC_VS_CRC.Mode=CRC_Activate
VP_DMA2D_VS_DMA2D.Mode=DMA2D_Activate
VP_FREERTOS_M7_VS_CMSIS_V2.Mode=CMSIS_V2
VP_JPEG_VS_JPEG.Mode=JPEG_Activate
VP_LTDC_DSIMode.Mode=RGB888
VP_STMicroelectronics.X-CUBE-TOUCHGFX_M7_VS_GraphicsJjApplication_4.25.0.Mode=GraphicsJjApplication
VP_SYS_M4_VS_Systick.Mode=SysTick
VP_SYS_VS_tim17.Mode=TIM17
VP_TIM14_VS_ClockSourceINT.Mode=Enable_Timer
VP_TIM2_VS_ClockSourceINT.Mode=Internal
VP_TIM2_VS_indirect_ch1.Mode=Input_Capture2_from_TI1_63
VP_TIM2_VS_indirect_ch3.Mode=Input_Capture4_from_TI3_63
VP_TIM5_VS_indirect_ch2.Mode=Input_Capture1_from_TI2_63
VP_TIM5_VS_indirect_ch4.Mode=Input_Capture3_from_TI4_63
VP_TIM8_VS_ClockSourceINT.Mode=Internal
VP_USB_DEVICE_M7_VS_USB_DEVICE_CDC_FS.Mode=CDC_FS
VREF+.Mode=InternalMode
VREF+.PinAttribute=CortexM7
VREF+.Signal=VREFBUF_OUT
VREFBUF.VoltageScaling=SYSCFG_VREFBUF_VOLTAGE_SCALE1
board=custom

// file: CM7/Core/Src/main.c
/* USER CODE BEGIN Header */
/**
  ******************************************************************************
  * @file           : main.c
  * @brief          : Main program body
  ******************************************************************************
  * @attention
  *
  * Copyright (c) 2025 STMicroelectronics.
  * All rights reserved.
  *
  * This software is licensed under terms that can be found in the LICENSE file
  * in the root directory of this software component.
  * If no LICENSE file comes with this software, it is provided AS-IS.
  *
  ******************************************************************************
  */
/* USER CODE END Header */
#include "main.h"
#include "cmsis_os.h"
#include "app_touchgfx.h"
#include "usb_device.h"

/* USER CODE BEGIN PD */

#ifndef HSEM_ID_0
#define HSEM_ID_0 (0U) /* HW semaphore 0*/
#endif

/* USER CODE END PD */

/* USER CODE BEGIN PM */

#define  HSYNC             (30) //30
#define  HBP               (60) //30
#define  HFP               (144) //90
#define  VSYNC             (2) //2
#define  VBP               (48) //4
#define  VFP               (36) //2

#define WIDTH   1920
#define HEIGHT  720

#define DSI_LANE_BYTE_CLK (62500 * 1)
#define LTDC_PIXEL_CLK    (41666 * 1)
#define DSI_NUM_CHUNKS    (1) //4/1
#define DSI_NULL_PACK_SZ  (0) // 84/372

/* USER CODE END PM */

ADC_HandleTypeDef hadc3;
DMA_HandleTypeDef hdma_adc3;

CRC_HandleTypeDef hcrc;

DMA2D_HandleTypeDef hdma2d;

DSI_HandleTypeDef hdsi;

FDCAN_HandleTypeDef hfdcan1;

I2C_HandleTypeDef hi2c2;

JPEG_HandleTypeDef hjpeg;

LTDC_HandleTypeDef hltdc;

QSPI_HandleTypeDef hqspi;

SPI_HandleTypeDef hspi1;
DMA_HandleTypeDef hdma_spi1_rx;
DMA_HandleTypeDef hdma_spi1_tx;

TIM_HandleTypeDef htim2;
TIM_HandleTypeDef htim5;
TIM_HandleTypeDef htim8;
TIM_HandleTypeDef htim14;

UART_HandleTypeDef huart1;
DMA_HandleTypeDef hdma_usart1_rx;
DMA_HandleTypeDef hdma_usart1_tx;

SDRAM_HandleTypeDef hsdram1;
SDRAM_HandleTypeDef hsdram2;

/* Definitions for defaultTask */

/* Definitions for defaultTask */
osThreadId_t defaultTaskHandle;
osThreadId_t touchgfxTaskHandle;

const osThreadAttr_t defaultTask_attributes = {
  .name = "Task_Default",
  .stack_size = 3072 * 4,
  .priority = (osPriority_t) osPriorityNormal,
};

const osThreadAttr_t touchgfxTask_attributes = {
  .name = "Task_TouchGFX",
  .stack_size = 3072 * 4,
  .priority = (osPriority_t) osPriorityNormal,
};
/* USER CODE BEGIN PV */
extern const uint32_t __tgfx_framebuffer_start;
extern const uint32_t __tgfx_framebuffer_end;

extern const uint32_t __tgfx_extflash_loadaddr;
extern const uint32_t __tgfx_extflash_start;
extern const uint32_t __tgfx_extflash_end;
/* USER CODE END PV */

void SystemClock_Config(void);
void PeriphCommonClock_Config(void);
static void MPU_Config(void);
static void MX_GPIO_Init(void);
static void MX_BDMA_Init(void);
static void MX_DMA_Init(void);
static void MX_CRC_Init(void);
static void MX_DMA2D_Init(void);
static void MX_DSIHOST_DSI_Init(void);
static void MX_FMC_Init(void);
static void MX_JPEG_Init(void);
static void MX_LTDC_Init(void);
static void MX_QUADSPI_Init(void);
static void MX_USART1_UART_Init(void);
static void MX_ADC3_Init(void);
static void MX_FDCAN1_Init(void);
static void MX_I2C2_Init(void);
static void MX_SPI1_Init(void);
static void MX_TIM2_Init(void);
static void MX_TIM5_Init(void);
static void MX_TIM8_Init(void);
static void MX_TIM14_Init(void);
void StartDefaultTask(void *argument);

/* USER CODE BEGIN PFP */
volatile uint8_t i2c_flag = 0;
/* USER CODE END PFP */

/* USER CODE BEGIN 0 */
void i2c_write(uint8_t reg, uint8_t data)
{
  uint8_t bytes[2] = {reg, data};

  i2c_flag = 0;
  if(HAL_I2C_Master_Transmit_IT(&hi2c2, 0x58, bytes, 2) != HAL_OK) {
    Error_Handler();
  }
  while(i2c_flag == 0) {}
}

void i2c_read(uint8_t reg, uint8_t *data)
{

  i2c_flag = 0;
  if(HAL_I2C_Master_Transmit_IT(&hi2c2, 0x58, &reg, 1) != HAL_OK) {
    Error_Handler();
  }
  while(i2c_flag == 0) {}
  i2c_flag = 0;
  if(HAL_I2C_Master_Receive_IT(&hi2c2, 0x58, data, 1) != HAL_OK) {
    Error_Handler();
  }
  while(i2c_flag == 0) {}
}

void HAL_I2C_MasterTxCpltCallback(I2C_HandleTypeDef *hi2c)
{
  if(hi2c == &hi2c2) {
    i2c_flag = 1;
  }
}

void HAL_I2C_MasterRxCpltCallback(I2C_HandleTypeDef *hi2c)
{
  if(hi2c == &hi2c2) {
    i2c_flag = 1;
  }
}

void HAL_I2C_ErrorCallback(I2C_HandleTypeDef *hi2c)
{
  if(hi2c == &hi2c2) {
    i2c_flag = 1;
  }
}

extern void __libc_init_array(void);
/* USER CODE END 0 */

int main(void)
{

/* USER CODE BEGIN Boot_Mode_Sequence_0 */
  int32_t timeout;
/* USER CODE END Boot_Mode_Sequence_0 */

  /* MPU Configuration--------------------------------------------------------*/
  MPU_Config();

  /* Enable the CPU Cache */

  /* Enable I-Cache---------------------------------------------------------*/
  SCB_EnableICache();

  /* Enable D-Cache---------------------------------------------------------*/
  SCB_EnableDCache();

/* USER CODE BEGIN Boot_Mode_Sequence_1 */
  /* Wait until CPU2 boots and enters in stop mode or timeout*/
  timeout = 0xFFFF;
  while((__HAL_RCC_GET_FLAG(RCC_FLAG_D2CKRDY) != RESET) && (timeout-- > 0));
  if ( timeout < 0 )
  {
  Error_Handler();
  }
/* USER CODE END Boot_Mode_Sequence_1 */
  /* MCU Configuration--------------------------------------------------------*/

  /* Reset of all peripherals, Initializes the Flash interface and the Systick. */
  HAL_Init();

  /* Configure the system clock */
  SystemClock_Config();

  /* Configure the peripherals common clocks */
  PeriphCommonClock_Config();
/* USER CODE BEGIN Boot_Mode_Sequence_2 */
/* When system initialization is finished, Cortex-M7 will release Cortex-M4 by means of
HSEM notification */
/*HW semaphore Clock enable*/
__HAL_RCC_HSEM_CLK_ENABLE();
/*Take HSEM */
HAL_HSEM_FastTake(HSEM_ID_0);
/*Release HSEM in order to notify the CPU2(CM4)*/
HAL_HSEM_Release(HSEM_ID_0,0);
/* wait until CPU2 wakes up from stop mode */
timeout = 0xFFFF;
while((__HAL_RCC_GET_FLAG(RCC_FLAG_D2CKRDY) == RESET) && (timeout-- > 0));
if ( timeout < 0 )
{
Error_Handler();
}
/* USER CODE END Boot_Mode_Sequence_2 */

  /* Initialize all configured peripherals */
  MX_GPIO_Init();
  MX_BDMA_Init();
  MX_DMA_Init();
  MX_CRC_Init();
  MX_DMA2D_Init();
  MX_DSIHOST_DSI_Init();
  MX_FMC_Init();
  MX_JPEG_Init();
  MX_LTDC_Init();
  MX_QUADSPI_Init();
  MX_USART1_UART_Init();
  MX_ADC3_Init();
  MX_FDCAN1_Init();
  MX_I2C2_Init();
  MX_SPI1_Init();
  MX_TIM2_Init();
  MX_TIM5_Init();
  MX_TIM8_Init();
  MX_TIM14_Init();
  /* USER CODE BEGIN 2 */
  HAL_GPIO_WritePin(DSI_EN_GPIO_Port, DSI_EN_Pin, GPIO_PIN_RESET);

  if(HAL_DSI_Start(&hdsi) != HAL_OK) {
    Error_Handler();
  }
  HAL_Delay(20);

  HAL_GPIO_WritePin(DSI_EN_GPIO_Port, DSI_EN_Pin, GPIO_PIN_SET);

  HAL_Delay(20);

  i2c_write(0x09, 0x00);
  i2c_write(0x0D, 0x00);

  i2c_write(0x0A, 0x03);
  i2c_write(0x0B, 0x58);

  i2c_write(0x0D, 0x01);

  i2c_write(0x10, 0x36);

  i2c_write(0x11, 0x00);
  i2c_write(0x12, 0x2E);

  i2c_write(0x18, 0x6C);
  i2c_write(0x19, 0x05);
  i2c_write(0x1A, 0x40);
  i2c_write(0x1B, 0x00);

  i2c_write(0x20, WIDTH & 0xFF);
  i2c_write(0x21, WIDTH >> 8);

  i2c_write(0x24, HEIGHT & 0xFF);
  i2c_write(0x25, HEIGHT >> 8);

  i2c_write(0x28, 32); //TODO
  i2c_write(0x29, 0); //TODO

  i2c_write(0x2C, HSYNC & 0xFF);
  i2c_write(0x2D, HSYNC >> 8);

  i2c_write(0x30, VSYNC & 0xFF);
  i2c_write(0x31, VSYNC >> 8);

  i2c_write(0x34, HBP);
  i2c_write(0x35, 0);

  i2c_write(0x36, VBP);
  i2c_write(0x37, 0);

  i2c_write(0x38, HFP);
  i2c_write(0x39, 0);

  i2c_write(0x3A, VFP);
  i2c_write(0x3B, 0);

  i2c_write(0x3C, 0x00); //Test pattern

  i2c_write(0xE0, 0x01);
  i2c_write(0xE1, 0x00);
  i2c_write(0xE5, 0x00);

  i2c_write(0xF9, 0b00110);

  i2c_write(0x0D, 0x01);
  HAL_Delay(10);
  i2c_write(0x09, 0x01);

  HAL_Delay(10);

  i2c_write(0xE5, 0xFF);

  /*
   * 100 - almost off
   * 90 - minimum
   * 30 - maximum
   */

  htim14.Instance->CCR1 = 70;
  HAL_TIM_PWM_Start(&htim14, TIM_CHANNEL_1);

  HAL_Delay(100);

  HAL_GPIO_WritePin(BL_CTRL_GPIO_Port, BL_CTRL_Pin, GPIO_PIN_SET);

  HAL_GPIO_WritePin(BL_EN_GPIO_Port, BL_EN_Pin, GPIO_PIN_SET);

  /* USER CODE END 2 */

  /* Init scheduler */
  osKernelInitialize();

  __libc_init_array();

  MX_TouchGFX_Init();
  /* Call PreOsInit function */
  MX_TouchGFX_PreOSInit();

  /* Create the thread(s) */
  /* creation of defaultTask */
  touchgfxTaskHandle = osThreadNew(TouchGFX_Task, NULL, &touchgfxTask_attributes);

  defaultTaskHandle = osThreadNew(StartDefaultTask, NULL, &defaultTask_attributes);

  /* Start scheduler */
  osKernelStart();

  /* We should never get here as control is now taken by the scheduler */

  /* Infinite loop */
  while (1)
  {

  }
}

void SystemClock_Config(void)
{
  RCC_OscInitTypeDef RCC_OscInitStruct = {0};
  RCC_ClkInitTypeDef RCC_ClkInitStruct = {0};

  /** Supply configuration update enable
  */
  HAL_PWREx_ConfigSupply(PWR_DIRECT_SMPS_SUPPLY);

  /** Configure the main internal regulator output voltage
  */
  __HAL_PWR_VOLTAGESCALING_CONFIG(PWR_REGULATOR_VOLTAGE_SCALE0);

  while(!__HAL_PWR_GET_FLAG(PWR_FLAG_VOSRDY)) {}

  /** Initializes the RCC Oscillators according to the specified parameters
  * in the RCC_OscInitTypeDef structure.
  */
  RCC_OscInitStruct.OscillatorType = RCC_OSCILLATORTYPE_HSE;
  RCC_OscInitStruct.HSEState = RCC_HSE_BYPASS;
  RCC_OscInitStruct.PLL.PLLState = RCC_PLL_ON;
  RCC_OscInitStruct.PLL.PLLSource = RCC_PLLSOURCE_HSE;
  RCC_OscInitStruct.PLL.PLLM = 4;
  RCC_OscInitStruct.PLL.PLLN = 480;
  RCC_OscInitStruct.PLL.PLLP = 2;
  RCC_OscInitStruct.PLL.PLLQ = 20;
  RCC_OscInitStruct.PLL.PLLR = 4;
  RCC_OscInitStruct.PLL.PLLRGE = RCC_PLL1VCIRANGE_1;
  RCC_OscInitStruct.PLL.PLLVCOSEL = RCC_PLL1VCOWIDE;
  RCC_OscInitStruct.PLL.PLLFRACN = 0;
  if (HAL_RCC_OscConfig(&RCC_OscInitStruct) != HAL_OK)
  {
    Error_Handler();
  }

  /** Initializes the CPU, AHB and APB buses clocks
  */
  RCC_ClkInitStruct.ClockType = RCC_CLOCKTYPE_HCLK|RCC_CLOCKTYPE_SYSCLK
                              |RCC_CLOCKTYPE_PCLK1|RCC_CLOCKTYPE_PCLK2
                              |RCC_CLOCKTYPE_D3PCLK1|RCC_CLOCKTYPE_D1PCLK1;
  RCC_ClkInitStruct.SYSCLKSource = RCC_SYSCLKSOURCE_PLLCLK;
  RCC_ClkInitStruct.SYSCLKDivider = RCC_SYSCLK_DIV1;
  RCC_ClkInitStruct.AHBCLKDivider = RCC_HCLK_DIV2;
  RCC_ClkInitStruct.APB3CLKDivider = RCC_APB3_DIV2;
  RCC_ClkInitStruct.APB1CLKDivider = RCC_APB1_DIV2;
  RCC_ClkInitStruct.APB2CLKDivider = RCC_APB2_DIV2;
  RCC_ClkInitStruct.APB4CLKDivider = RCC_APB4_DIV2;

  if (HAL_RCC_ClockConfig(&RCC_ClkInitStruct, FLASH_LATENCY_4) != HAL_OK)
  {
    Error_Handler();
  }
}

void PeriphCommonClock_Config(void)
{
  RCC_PeriphCLKInitTypeDef PeriphClkInitStruct = {0};

  /** Initializes the peripherals clock
  */
  PeriphClkInitStruct.PeriphClockSelection = RCC_PERIPHCLK_FMC|RCC_PERIPHCLK_ADC
                              |RCC_PERIPHCLK_SPI1;
  PeriphClkInitStruct.PLL2.PLL2M = 4;
  PeriphClkInitStruct.PLL2.PLL2N = 266;
  PeriphClkInitStruct.PLL2.PLL2P = 14;
  PeriphClkInitStruct.PLL2.PLL2Q = 2;
  PeriphClkInitStruct.PLL2.PLL2R = 2;
  PeriphClkInitStruct.PLL2.PLL2RGE = RCC_PLL2VCIRANGE_1;
  PeriphClkInitStruct.PLL2.PLL2VCOSEL = RCC_PLL2VCOWIDE;
  PeriphClkInitStruct.PLL2.PLL2FRACN = 0;
  PeriphClkInitStruct.FmcClockSelection = RCC_FMCCLKSOURCE_PLL2;
  PeriphClkInitStruct.Spi123ClockSelection = RCC_SPI123CLKSOURCE_PLL2;
  PeriphClkInitStruct.AdcClockSelection = RCC_ADCCLKSOURCE_PLL2;
  if (HAL_RCCEx_PeriphCLKConfig(&PeriphClkInitStruct) != HAL_OK)
  {
    Error_Handler();
  }

  /** Initializes the peripherals clock
  */
  PeriphClkInitStruct.PeriphClockSelection = RCC_PERIPHCLK_LTDC|RCC_PERIPHCLK_USB
                              |RCC_PERIPHCLK_QSPI;
  PeriphClkInitStruct.PLL3.PLL3M = 4 * 2; // 4 * 2
  PeriphClkInitStruct.PLL3.PLL3N = 375;
  PeriphClkInitStruct.PLL3.PLL3P = 2;
  PeriphClkInitStruct.PLL3.PLL3Q = 12;
  PeriphClkInitStruct.PLL3.PLL3R = 9;
  PeriphClkInitStruct.PLL3.PLL3RGE = RCC_PLL3VCIRANGE_1;
  PeriphClkInitStruct.PLL3.PLL3VCOSEL = RCC_PLL3VCOWIDE;
  PeriphClkInitStruct.PLL3.PLL3FRACN = 0;
  PeriphClkInitStruct.UsbClockSelection = RCC_USBCLKSOURCE_PLL;
  PeriphClkInitStruct.QspiClockSelection = RCC_QSPICLKSOURCE_PLL;
  if (HAL_RCCEx_PeriphCLKConfig(&PeriphClkInitStruct) != HAL_OK)
  {
    Error_Handler();
  }
}

static void MX_ADC3_Init(void)
{

  ADC_ChannelConfTypeDef sConfig = {0};

  /** Common config
  */
  hadc3.Instance = ADC3;
  hadc3.Init.ClockPrescaler = ADC_CLOCK_ASYNC_DIV1;
  hadc3.Init.ScanConvMode = ADC_SCAN_ENABLE;
  hadc3.Init.EOCSelection = ADC_EOC_SEQ_CONV;
  hadc3.Init.LowPowerAutoWait = DISABLE;
  hadc3.Init.ContinuousConvMode = DISABLE;
  hadc3.Init.NbrOfConversion = 2;
  hadc3.Init.DiscontinuousConvMode = DISABLE;
  hadc3.Init.ExternalTrigConv = ADC_EXTERNALTRIG_T8_TRGO;
  hadc3.Init.ExternalTrigConvEdge = ADC_EXTERNALTRIGCONVEDGE_RISING;
  hadc3.Init.ConversionDataManagement = ADC_CONVERSIONDATA_DR;
  hadc3.Init.Overrun = ADC_OVR_DATA_PRESERVED;
  hadc3.Init.LeftBitShift = ADC_LEFTBITSHIFT_NONE;
  hadc3.Init.OversamplingMode = DISABLE;
  hadc3.Init.Oversampling.Ratio = 1;
  if (HAL_ADC_Init(&hadc3) != HAL_OK)
  {
    Error_Handler();
  }

  /** Configure Regular Channel
  */
  sConfig.Channel = ADC_CHANNEL_0;
  sConfig.Rank = ADC_REGULAR_RANK_1;
  sConfig.SamplingTime = ADC_SAMPLETIME_64CYCLES_5;
  sConfig.SingleDiff = ADC_SINGLE_ENDED;
  sConfig.OffsetNumber = ADC_OFFSET_NONE;
  sConfig.Offset = 0;
  sConfig.OffsetSignedSaturation = DISABLE;
  if (HAL_ADC_ConfigChannel(&hadc3, &sConfig) != HAL_OK)
  {
    Error_Handler();
  }

  /** Configure Regular Channel
  */
  sConfig.Channel = ADC_CHANNEL_1;
  sConfig.Rank = ADC_REGULAR_RANK_2;
  if (HAL_ADC_ConfigChannel(&hadc3, &sConfig) != HAL_OK)
  {
    Error_Handler();
  }

}

static void MX_CRC_Init(void)
{

  hcrc.Instance = CRC;
  hcrc.Init.DefaultPolynomialUse = DEFAULT_POLYNOMIAL_ENABLE;
  hcrc.Init.DefaultInitValueUse = DEFAULT_INIT_VALUE_ENABLE;
  hcrc.Init.InputDataInversionMode = CRC_INPUTDATA_INVERSION_NONE;
  hcrc.Init.OutputDataInversionMode = CRC_OUTPUTDATA_INVERSION_DISABLE;
  hcrc.InputDataFormat = CRC_INPUTDATA_FORMAT_BYTES;
  if (HAL_CRC_Init(&hcrc) != HAL_OK)
  {
    Error_Handler();
  }

}

static void MX_DMA2D_Init(void)
{

  hdma2d.Instance = DMA2D;
  hdma2d.Init.Mode = DMA2D_M2M;
  hdma2d.Init.ColorMode = DMA2D_OUTPUT_ARGB8888;
  hdma2d.Init.OutputOffset = 0;
  hdma2d.LayerCfg[1].InputOffset = 0;
  hdma2d.LayerCfg[1].InputColorMode = DMA2D_INPUT_ARGB8888;
  hdma2d.LayerCfg[1].AlphaMode = DMA2D_NO_MODIF_ALPHA;
  hdma2d.LayerCfg[1].InputAlpha = 0;
  hdma2d.LayerCfg[1].AlphaInverted = DMA2D_REGULAR_ALPHA;
  hdma2d.LayerCfg[1].RedBlueSwap = DMA2D_RB_REGULAR;
  hdma2d.LayerCfg[1].ChromaSubSampling = DMA2D_NO_CSS;
  if (HAL_DMA2D_Init(&hdma2d) != HAL_OK)
  {
    Error_Handler();
  }
  if (HAL_DMA2D_ConfigLayer(&hdma2d, 1) != HAL_OK)
  {
    Error_Handler();
  }

}

static void MX_DSIHOST_DSI_Init(void)
{

  DSI_PLLInitTypeDef PLLInit = {0};
  DSI_VidCfgTypeDef VidCfg = {0};

  hdsi.Instance = DSI;
  hdsi.Init.AutomaticClockLaneControl = DSI_AUTO_CLK_LANE_CTRL_DISABLE;
  hdsi.Init.TXEscapeCkdiv = 4;
  hdsi.Init.NumberOfLanes = DSI_TWO_DATA_LANES;
  PLLInit.PLLNDIV = 125;
  PLLInit.PLLIDF = DSI_PLL_IN_DIV1;
  PLLInit.PLLODF = DSI_PLL_OUT_DIV2;
  if (HAL_DSI_Init(&hdsi, &PLLInit) != HAL_OK)
  {
    Error_Handler();
  }

  DSI_PHY_TimerTypeDef PhyTimings = {0};
  PhyTimings.ClockLaneHS2LPTime = 0x14;
  PhyTimings.ClockLaneLP2HSTime = 0x14;
  PhyTimings.DataLaneHS2LPTime = 0x0A;
  PhyTimings.DataLaneLP2HSTime = 0x0A;
  PhyTimings.DataLaneMaxReadTime = 0;
  PhyTimings.StopWaitTime = 0;
  if (HAL_DSI_ConfigPhyTimer(&hdsi, &PhyTimings) != HAL_OK)
  {
    Error_Handler();
  }

  VidCfg.VirtualChannelID = 0;
  VidCfg.ColorCoding = DSI_RGB888;
  VidCfg.LooselyPacked = DSI_LOOSELY_PACKED_DISABLE;
  VidCfg.Mode = DSI_VID_MODE_BURST;
  VidCfg.PacketSize = WIDTH / DSI_NUM_CHUNKS;
  VidCfg.NumberOfChunks = DSI_NUM_CHUNKS;
  VidCfg.NullPacketSize = DSI_NULL_PACK_SZ;
  VidCfg.HSPolarity = DSI_HSYNC_ACTIVE_LOW;
  VidCfg.VSPolarity = DSI_VSYNC_ACTIVE_LOW;
  VidCfg.DEPolarity = DSI_DATA_ENABLE_ACTIVE_HIGH;
  VidCfg.HorizontalSyncActive = (HSYNC * DSI_LANE_BYTE_CLK) / LTDC_PIXEL_CLK;
  VidCfg.HorizontalBackPorch = (HBP * DSI_LANE_BYTE_CLK) / LTDC_PIXEL_CLK;
  VidCfg.HorizontalLine = ((WIDTH + HSYNC + HBP + HFP) * DSI_LANE_BYTE_CLK) / LTDC_PIXEL_CLK;
  VidCfg.VerticalSyncActive = VSYNC;
  VidCfg.VerticalBackPorch = VBP;
  VidCfg.VerticalFrontPorch = VFP;
  VidCfg.VerticalActive = HEIGHT;
  VidCfg.LPCommandEnable = DSI_LP_COMMAND_DISABLE;
  VidCfg.LPLargestPacketSize = 4;
  VidCfg.LPVACTLargestPacketSize = 4;
  VidCfg.LPHorizontalFrontPorchEnable = DSI_LP_HFP_ENABLE;
  VidCfg.LPHorizontalBackPorchEnable = DSI_LP_HBP_ENABLE;
  VidCfg.LPVerticalActiveEnable = DSI_LP_VACT_DISABLE;
  VidCfg.LPVerticalFrontPorchEnable = DSI_LP_VFP_DISABLE;
  VidCfg.LPVerticalBackPorchEnable = DSI_LP_VBP_DISABLE;
  VidCfg.LPVerticalSyncActiveEnable = DSI_LP_VSYNC_DISABLE;
  VidCfg.FrameBTAAcknowledgeEnable = DSI_FBTAA_DISABLE;
  if (HAL_DSI_ConfigVideoMode(&hdsi, &VidCfg) != HAL_OK)
  {
    Error_Handler();
  }

}

static void MX_FDCAN1_Init(void)
{

  hfdcan1.Instance = FDCAN1;
  hfdcan1.Init.FrameFormat = FDCAN_FRAME_CLASSIC;
  hfdcan1.Init.Mode = FDCAN_MODE_NORMAL;
  hfdcan1.Init.AutoRetransmission = ENABLE;
  hfdcan1.Init.TransmitPause = DISABLE;
  hfdcan1.Init.ProtocolException = DISABLE;
  hfdcan1.Init.NominalPrescaler = 12;
  hfdcan1.Init.NominalSyncJumpWidth = 1;
  hfdcan1.Init.NominalTimeSeg1 = 1;
  hfdcan1.Init.NominalTimeSeg2 = 1;
  hfdcan1.Init.DataPrescaler = 1;
  hfdcan1.Init.DataSyncJumpWidth = 1;
  hfdcan1.Init.DataTimeSeg1 = 4;
  hfdcan1.Init.DataTimeSeg2 = 3;
  hfdcan1.Init.MessageRAMOffset = 0;
  hfdcan1.Init.StdFiltersNbr = 0;
  hfdcan1.Init.ExtFiltersNbr = 0;
  hfdcan1.Init.RxFifo0ElmtsNbr = 64;
  hfdcan1.Init.RxFifo0ElmtSize = FDCAN_DATA_BYTES_8;
  hfdcan1.Init.RxFifo1ElmtsNbr = 64;
  hfdcan1.Init.RxFifo1ElmtSize = FDCAN_DATA_BYTES_8;
  hfdcan1.Init.RxBuffersNbr = 64;
  hfdcan1.Init.RxBufferSize = FDCAN_DATA_BYTES_8;
  hfdcan1.Init.TxEventsNbr = 32;
  hfdcan1.Init.TxBuffersNbr = 32;
  hfdcan1.Init.TxFifoQueueElmtsNbr = 0;
  hfdcan1.Init.TxFifoQueueMode = FDCAN_TX_FIFO_OPERATION;
  hfdcan1.Init.TxElmtSize = FDCAN_DATA_BYTES_8;
  if (HAL_FDCAN_Init(&hfdcan1) != HAL_OK)
  {
    Error_Handler();
  }

}

static void MX_I2C2_Init(void)
{

  hi2c2.Instance = I2C2;
  hi2c2.Init.Timing = 0x307075B1;
  hi2c2.Init.OwnAddress1 = 0;
  hi2c2.Init.AddressingMode = I2C_ADDRESSINGMODE_7BIT;
  hi2c2.Init.DualAddressMode = I2C_DUALADDRESS_DISABLE;
  hi2c2.Init.OwnAddress2 = 0;
  hi2c2.Init.OwnAddress2Masks = I2C_OA2_NOMASK;
  hi2c2.Init.GeneralCallMode = I2C_GENERALCALL_DISABLE;
  hi2c2.Init.NoStretchMode = I2C_NOSTRETCH_DISABLE;
  if (HAL_I2C_Init(&hi2c2) != HAL_OK)
  {
    Error_Handler();
  }

  /** Configure Analogue filter
  */
  if (HAL_I2CEx_ConfigAnalogFilter(&hi2c2, I2C_ANALOGFILTER_ENABLE) != HAL_OK)
  {
    Error_Handler();
  }

  /** Configure Digital filter
  */
  if (HAL_I2CEx_ConfigDigitalFilter(&hi2c2, 0) != HAL_OK)
  {
    Error_Handler();
  }

}

static void MX_JPEG_Init(void)
{

  hjpeg.Instance = JPEG;
  if (HAL_JPEG_Init(&hjpeg) != HAL_OK)
  {
    Error_Handler();
  }

}

static void MX_LTDC_Init(void)
{

  LTDC_LayerCfgTypeDef pLayerCfg = {0};

  hltdc.Instance = LTDC;
  hltdc.Init.HSPolarity = LTDC_HSPOLARITY_AL;
  hltdc.Init.VSPolarity = LTDC_VSPOLARITY_AL;
  hltdc.Init.DEPolarity = LTDC_DEPOLARITY_AL;
  hltdc.Init.PCPolarity = LTDC_PCPOLARITY_IPC;

  hltdc.Init.HorizontalSync     = HSYNC - 1;
  hltdc.Init.AccumulatedHBP     = HSYNC + HBP - 1;
  hltdc.Init.AccumulatedActiveW = HSYNC + WIDTH + HBP - 1;
  hltdc.Init.TotalWidth         = HSYNC + WIDTH + HBP + HFP - 1;

  hltdc.Init.VerticalSync       = VSYNC - 1;
  hltdc.Init.AccumulatedVBP     = VSYNC + VBP - 1;
  hltdc.Init.AccumulatedActiveH = VSYNC + HEIGHT + VBP - 1;
  hltdc.Init.TotalHeigh         = VSYNC + HEIGHT + VBP + VFP - 1;

  hltdc.Init.Backcolor.Blue = 255;
  hltdc.Init.Backcolor.Green = 0;
  hltdc.Init.Backcolor.Red = 0;

  if (HAL_LTDC_Init(&hltdc) != HAL_OK)
  {
    Error_Handler();
  }

  pLayerCfg.WindowX0 = 0;
  pLayerCfg.WindowX1 = WIDTH;
  pLayerCfg.WindowY0 = 0;
  pLayerCfg.WindowY1 = HEIGHT;
  pLayerCfg.PixelFormat = LTDC_PIXEL_FORMAT_RGB888;
  pLayerCfg.Alpha = 255;
  pLayerCfg.Alpha0 = 0;
  pLayerCfg.BlendingFactor1 = LTDC_BLENDING_FACTOR1_CA;
  pLayerCfg.BlendingFactor2 = LTDC_BLENDING_FACTOR2_CA;
  pLayerCfg.FBStartAdress = (uint32_t)&__tgfx_framebuffer_start;
  pLayerCfg.ImageWidth = WIDTH;
  pLayerCfg.ImageHeight = HEIGHT;
  pLayerCfg.Backcolor.Blue = 0;
  pLayerCfg.Backcolor.Green = 0;
  pLayerCfg.Backcolor.Red = 0;
  if (HAL_LTDC_ConfigLayer(&hltdc, &pLayerCfg, 0) != HAL_OK)
  {
    Error_Handler();
  }

}

static void MX_QUADSPI_Init(void)
{

  /* USER CODE BEGIN QUADSPI_Init 0 */
  QSPI_MemoryMappedTypeDef hqspi_memory_map;
  QSPI_CommandTypeDef hqspi_cmd;
  /* USER CODE END QUADSPI_Init 0 */

  /* QUADSPI parameter configuration*/
  hqspi.Instance = QUADSPI;
  hqspi.Init.ClockPrescaler = 0;
  hqspi.Init.FifoThreshold = 4;
  hqspi.Init.SampleShifting = QSPI_SAMPLE_SHIFTING_NONE;
  hqspi.Init.FlashSize = 24-1;
  hqspi.Init.ChipSelectHighTime = QSPI_CS_HIGH_TIME_1_CYCLE;
  hqspi.Init.ClockMode = QSPI_CLOCK_MODE_0;
  hqspi.Init.FlashID = QSPI_FLASH_ID_1;
  hqspi.Init.DualFlash = QSPI_DUALFLASH_DISABLE;
  if (HAL_QSPI_Init(&hqspi) != HAL_OK)
  {
    Error_Handler();
  }
  /* USER CODE BEGIN QUADSPI_Init 2 */

  memset(&hqspi_memory_map, 0, sizeof(hqspi_memory_map));
  hqspi_memory_map.TimeOutActivation = QSPI_TIMEOUT_COUNTER_DISABLE;
  hqspi_memory_map.TimeOutPeriod = 0;

  memset(&hqspi_cmd, 0, sizeof(hqspi_cmd));
  hqspi_cmd.Instruction = 0xFF;
  hqspi_cmd.InstructionMode = QSPI_INSTRUCTION_4_LINES;
  if(HAL_QSPI_Command(&hqspi, &hqspi_cmd, HAL_QPSI_TIMEOUT_DEFAULT_VALUE) != HAL_OK)
  {
    Error_Handler();
  }

  memset(&hqspi_cmd, 0, sizeof(hqspi_cmd));
  hqspi_cmd.Instruction = 0xFF;
  hqspi_cmd.InstructionMode = QSPI_INSTRUCTION_1_LINE;
  if(HAL_QSPI_Command(&hqspi, &hqspi_cmd, HAL_QPSI_TIMEOUT_DEFAULT_VALUE) != HAL_OK)
  {
    Error_Handler();
  }

  memset(&hqspi_cmd, 0, sizeof(hqspi_cmd));
  hqspi_cmd.Instruction = 0x66;
  hqspi_cmd.InstructionMode = QSPI_INSTRUCTION_1_LINE;
  if(HAL_QSPI_Command(&hqspi, &hqspi_cmd, HAL_QPSI_TIMEOUT_DEFAULT_VALUE) != HAL_OK)
  {
    Error_Handler();
  }

  memset(&hqspi_cmd, 0, sizeof(hqspi_cmd));
  hqspi_cmd.Instruction = 0x99;
  hqspi_cmd.InstructionMode = QSPI_INSTRUCTION_1_LINE;
  if(HAL_QSPI_Command(&hqspi, &hqspi_cmd, HAL_QPSI_TIMEOUT_DEFAULT_VALUE) != HAL_OK)
  {
    Error_Handler();
  }

  memset(&hqspi_cmd, 0, sizeof(hqspi_cmd));
  hqspi_cmd.Instruction = 0x38;
  hqspi_cmd.InstructionMode = QSPI_INSTRUCTION_1_LINE;
  if(HAL_QSPI_Command(&hqspi, &hqspi_cmd, HAL_QPSI_TIMEOUT_DEFAULT_VALUE) != HAL_OK)
  {
    Error_Handler();
  }

  memset(&hqspi_cmd, 0, sizeof(hqspi_cmd));
  hqspi_cmd.Instruction = 0x0B;
  hqspi_cmd.InstructionMode = QSPI_INSTRUCTION_4_LINES;
  hqspi_cmd.Address = 0x00;
  hqspi_cmd.AddressSize = QSPI_ADDRESS_24_BITS;
  hqspi_cmd.AddressMode = QSPI_ADDRESS_4_LINES;
  hqspi_cmd.DummyCycles = 2;
  hqspi_cmd.DataMode = QSPI_DATA_4_LINES;
  hqspi_cmd.NbData = 0;

  if(HAL_QSPI_MemoryMapped(&hqspi, &hqspi_cmd, &hqspi_memory_map) != HAL_OK)
  {
    Error_Handler();
  }

  uint32_t * const src = (uint32_t *)&__tgfx_extflash_loadaddr;
  uint32_t * const dst = (uint32_t *)&__tgfx_extflash_start;
  const uint32_t size = (&__tgfx_extflash_end - &__tgfx_extflash_start) * sizeof(uint32_t);

  SCB_InvalidateDCache_by_Addr(src, size);
  memcpy(dst, src, size);
  SCB_CleanDCache_by_Addr(dst, size);

  /* USER CODE END QUADSPI_Init 2 */

}

static void MX_SPI1_Init(void)
{

  /* SPI1 parameter configuration*/
  hspi1.Instance = SPI1;
  hspi1.Init.Mode = SPI_MODE_MASTER;
  hspi1.Init.Direction = SPI_DIRECTION_2LINES;
  hspi1.Init.DataSize = SPI_DATASIZE_8BIT;
  hspi1.Init.CLKPolarity = SPI_POLARITY_LOW;
  hspi1.Init.CLKPhase = SPI_PHASE_1EDGE;
  hspi1.Init.NSS = SPI_NSS_SOFT;
  hspi1.Init.BaudRatePrescaler = SPI_BAUDRATEPRESCALER_4;
  hspi1.Init.FirstBit = SPI_FIRSTBIT_MSB;
  hspi1.Init.TIMode = SPI_TIMODE_DISABLE;
  hspi1.Init.CRCCalculation = SPI_CRCCALCULATION_DISABLE;
  hspi1.Init.CRCPolynomial = 0x0;
  hspi1.Init.NSSPMode = SPI_NSS_PULSE_ENABLE;
  hspi1.Init.NSSPolarity = SPI_NSS_POLARITY_LOW;
  hspi1.Init.FifoThreshold = SPI_FIFO_THRESHOLD_01DATA;
  hspi1.Init.TxCRCInitializationPattern = SPI_CRC_INITIALIZATION_ALL_ZERO_PATTERN;
  hspi1.Init.RxCRCInitializationPattern = SPI_CRC_INITIALIZATION_ALL_ZERO_PATTERN;
  hspi1.Init.MasterSSIdleness = SPI_MASTER_SS_IDLENESS_00CYCLE;
  hspi1.Init.MasterInterDataIdleness = SPI_MASTER_INTERDATA_IDLENESS_00CYCLE;
  hspi1.Init.MasterReceiverAutoSusp = SPI_MASTER_RX_AUTOSUSP_DISABLE;
  hspi1.Init.MasterKeepIOState = SPI_MASTER_KEEP_IO_STATE_DISABLE;
  hspi1.Init.IOSwap = SPI_IO_SWAP_DISABLE;
  if (HAL_SPI_Init(&hspi1) != HAL_OK)
  {
    Error_Handler();
  }

}

static void MX_TIM2_Init(void)
{

  TIM_ClockConfigTypeDef sClockSourceConfig = {0};
  TIM_MasterConfigTypeDef sMasterConfig = {0};
  TIM_IC_InitTypeDef sConfigIC = {0};

  htim2.Instance = TIM2;
  htim2.Init.Prescaler = 0;
  htim2.Init.CounterMode = TIM_COUNTERMODE_UP;
  htim2.Init.Period = 4294967295;
  htim2.Init.ClockDivision = TIM_CLOCKDIVISION_DIV1;
  htim2.Init.AutoReloadPreload = TIM_AUTORELOAD_PRELOAD_DISABLE;
  if (HAL_TIM_Base_Init(&htim2) != HAL_OK)
  {
    Error_Handler();
  }
  sClockSourceConfig.ClockSource = TIM_CLOCKSOURCE_INTERNAL;
  if (HAL_TIM_ConfigClockSource(&htim2, &sClockSourceConfig) != HAL_OK)
  {
    Error_Handler();
  }
  if (HAL_TIM_IC_Init(&htim2) != HAL_OK)
  {
    Error_Handler();
  }
  sMasterConfig.MasterOutputTrigger = TIM_TRGO_RESET;
  sMasterConfig.MasterSlaveMode = TIM_MASTERSLAVEMODE_DISABLE;
  if (HAL_TIMEx_MasterConfigSynchronization(&htim2, &sMasterConfig) != HAL_OK)
  {
    Error_Handler();
  }
  sConfigIC.ICPolarity = TIM_INPUTCHANNELPOLARITY_RISING;
  sConfigIC.ICSelection = TIM_ICSELECTION_DIRECTTI;
  sConfigIC.ICPrescaler = TIM_ICPSC_DIV1;
  sConfigIC.ICFilter = 0;
  if (HAL_TIM_IC_ConfigChannel(&htim2, &sConfigIC, TIM_CHANNEL_1) != HAL_OK)
  {
    Error_Handler();
  }
  sConfigIC.ICSelection = TIM_ICSELECTION_INDIRECTTI;
  if (HAL_TIM_IC_ConfigChannel(&htim2, &sConfigIC, TIM_CHANNEL_2) != HAL_OK)
  {
    Error_Handler();
  }
  sConfigIC.ICSelection = TIM_ICSELECTION_DIRECTTI;
  if (HAL_TIM_IC_ConfigChannel(&htim2, &sConfigIC, TIM_CHANNEL_3) != HAL_OK)
  {
    Error_Handler();
  }
  sConfigIC.ICSelection = TIM_ICSELECTION_INDIRECTTI;
  if (HAL_TIM_IC_ConfigChannel(&htim2, &sConfigIC, TIM_CHANNEL_4) != HAL_OK)
  {
    Error_Handler();
  }

}

static void MX_TIM5_Init(void)
{

  TIM_MasterConfigTypeDef sMasterConfig = {0};
  TIM_IC_InitTypeDef sConfigIC = {0};

  htim5.Instance = TIM5;
  htim5.Init.Prescaler = 0;
  htim5.Init.CounterMode = TIM_COUNTERMODE_UP;
  htim5.Init.Period = 4294967295;
  htim5.Init.ClockDivision = TIM_CLOCKDIVISION_DIV1;
  htim5.Init.AutoReloadPreload = TIM_AUTORELOAD_PRELOAD_DISABLE;
  if (HAL_TIM_IC_Init(&htim5) != HAL_OK)
  {
    Error_Handler();
  }
  sMasterConfig.MasterOutputTrigger = TIM_TRGO_RESET;
  sMasterConfig.MasterSlaveMode = TIM_MASTERSLAVEMODE_DISABLE;
  if (HAL_TIMEx_MasterConfigSynchronization(&htim5, &sMasterConfig) != HAL_OK)
  {
    Error_Handler();
  }
  sConfigIC.ICPolarity = TIM_INPUTCHANNELPOLARITY_RISING;
  sConfigIC.ICSelection = TIM_ICSELECTION_INDIRECTTI;
  sConfigIC.ICPrescaler = TIM_ICPSC_DIV1;
  sConfigIC.ICFilter = 0;
  if (HAL_TIM_IC_ConfigChannel(&htim5, &sConfigIC, TIM_CHANNEL_1) != HAL_OK)
  {
    Error_Handler();
  }
  sConfigIC.ICSelection = TIM_ICSELECTION_DIRECTTI;
  if (HAL_TIM_IC_ConfigChannel(&htim5, &sConfigIC, TIM_CHANNEL_2) != HAL_OK)
  {
    Error_Handler();
  }
  sConfigIC.ICSelection = TIM_ICSELECTION_INDIRECTTI;
  if (HAL_TIM_IC_ConfigChannel(&htim5, &sConfigIC, TIM_CHANNEL_3) != HAL_OK)
  {
    Error_Handler();
  }
  sConfigIC.ICSelection = TIM_ICSELECTION_DIRECTTI;
  if (HAL_TIM_IC_ConfigChannel(&htim5, &sConfigIC, TIM_CHANNEL_4) != HAL_OK)
  {
    Error_Handler();
  }

}

static void MX_TIM8_Init(void)
{

  TIM_ClockConfigTypeDef sClockSourceConfig = {0};
  TIM_MasterConfigTypeDef sMasterConfig = {0};

  htim8.Instance = TIM8;
  htim8.Init.Prescaler = 120-1;
  htim8.Init.CounterMode = TIM_COUNTERMODE_UP;
  htim8.Init.Period = 1000-1;
  htim8.Init.ClockDivision = TIM_CLOCKDIVISION_DIV1;
  htim8.Init.RepetitionCounter = 0;
  htim8.Init.AutoReloadPreload = TIM_AUTORELOAD_PRELOAD_DISABLE;
  if (HAL_TIM_Base_Init(&htim8) != HAL_OK)
  {
    Error_Handler();
  }
  sClockSourceConfig.ClockSource = TIM_CLOCKSOURCE_INTERNAL;
  if (HAL_TIM_ConfigClockSource(&htim8, &sClockSourceConfig) != HAL_OK)
  {
    Error_Handler();
  }
  sMasterConfig.MasterOutputTrigger = TIM_TRGO_UPDATE;
  sMasterConfig.MasterOutputTrigger2 = TIM_TRGO2_RESET;
  sMasterConfig.MasterSlaveMode = TIM_MASTERSLAVEMODE_DISABLE;
  if (HAL_TIMEx_MasterConfigSynchronization(&htim8, &sMasterConfig) != HAL_OK)
  {
    Error_Handler();
  }

}

static void MX_TIM14_Init(void)
{

  TIM_OC_InitTypeDef sConfigOC = {0};

  htim14.Instance = TIM14;
  htim14.Init.Prescaler = 12-1;
  htim14.Init.CounterMode = TIM_COUNTERMODE_UP;
  htim14.Init.Period = 256-1;
  htim14.Init.ClockDivision = TIM_CLOCKDIVISION_DIV1;
  htim14.Init.AutoReloadPreload = TIM_AUTORELOAD_PRELOAD_DISABLE;
  if (HAL_TIM_Base_Init(&htim14) != HAL_OK)
  {
    Error_Handler();
  }
  if (HAL_TIM_PWM_Init(&htim14) != HAL_OK)
  {
    Error_Handler();
  }
  sConfigOC.OCMode = TIM_OCMODE_PWM1;
  sConfigOC.Pulse = 0;
  sConfigOC.OCPolarity = TIM_OCPOLARITY_HIGH;
  sConfigOC.OCFastMode = TIM_OCFAST_DISABLE;
  if (HAL_TIM_PWM_ConfigChannel(&htim14, &sConfigOC, TIM_CHANNEL_1) != HAL_OK)
  {
    Error_Handler();
  }
  HAL_TIM_MspPostInit(&htim14);

}

static void MX_USART1_UART_Init(void)
{

  huart1.Instance = USART1;
  huart1.Init.BaudRate = 115200;
  huart1.Init.WordLength = UART_WORDLENGTH_8B;
  huart1.Init.StopBits = UART_STOPBITS_1;
  huart1.Init.Parity = UART_PARITY_NONE;
  huart1.Init.Mode = UART_MODE_TX_RX;
  huart1.Init.HwFlowCtl = UART_HWCONTROL_NONE;
  huart1.Init.OverSampling = UART_OVERSAMPLING_16;
  huart1.Init.OneBitSampling = UART_ONE_BIT_SAMPLE_DISABLE;
  huart1.Init.ClockPrescaler = UART_PRESCALER_DIV1;
  huart1.AdvancedInit.AdvFeatureInit = UART_ADVFEATURE_NO_INIT;
  if (HAL_UART_Init(&huart1) != HAL_OK)
  {
    Error_Handler();
  }
  if (HAL_UARTEx_SetTxFifoThreshold(&huart1, UART_TXFIFO_THRESHOLD_1_8) != HAL_OK)
  {
    Error_Handler();
  }
  if (HAL_UARTEx_SetRxFifoThreshold(&huart1, UART_RXFIFO_THRESHOLD_1_8) != HAL_OK)
  {
    Error_Handler();
  }
  if (HAL_UARTEx_DisableFifoMode(&huart1) != HAL_OK)
  {
    Error_Handler();
  }

}

static void MX_BDMA_Init(void)
{

  /* DMA controller clock enable */
  __HAL_RCC_BDMA_CLK_ENABLE();

  /* DMA interrupt init */
  /* BDMA_Channel0_IRQn interrupt configuration */
  HAL_NVIC_SetPriority(BDMA_Channel0_IRQn, 5, 0);
  HAL_NVIC_EnableIRQ(BDMA_Channel0_IRQn);

}

static void MX_DMA_Init(void)
{

  /* DMA controller clock enable */
  __HAL_RCC_DMA1_CLK_ENABLE();

  /* DMA interrupt init */
  /* DMA1_Stream0_IRQn interrupt configuration */
  HAL_NVIC_SetPriority(DMA1_Stream0_IRQn, 5, 0);
  HAL_NVIC_EnableIRQ(DMA1_Stream0_IRQn);
  /* DMA1_Stream1_IRQn interrupt configuration */
  HAL_NVIC_SetPriority(DMA1_Stream1_IRQn, 5, 0);
  HAL_NVIC_EnableIRQ(DMA1_Stream1_IRQn);
  /* DMA1_Stream2_IRQn interrupt configuration */
  HAL_NVIC_SetPriority(DMA1_Stream2_IRQn, 5, 0);
  HAL_NVIC_EnableIRQ(DMA1_Stream2_IRQn);
  /* DMA1_Stream3_IRQn interrupt configuration */
  HAL_NVIC_SetPriority(DMA1_Stream3_IRQn, 5, 0);
  HAL_NVIC_EnableIRQ(DMA1_Stream3_IRQn);

}

/* FMC initialization function */
void MX_FMC_Init(void)
{

  FMC_SDRAM_TimingTypeDef SdramTiming = {0};

  /* USER CODE BEGIN FMC_Init 1 */

  FMC_SDRAM_CommandTypeDef Command = {0};

  /* USER CODE END FMC_Init 1 */

  /* SdramTiming */
  SdramTiming.LoadToActiveDelay = 2;
  SdramTiming.ExitSelfRefreshDelay = 9;
  SdramTiming.SelfRefreshTime = 5;
  SdramTiming.RowCycleDelay = 7;
  SdramTiming.WriteRecoveryTime = 3;
  SdramTiming.RPDelay = 2;
  SdramTiming.RCDDelay = 2;

  /** Perform the SDRAM1 memory initialization sequence
  */
  hsdram1.Instance = FMC_SDRAM_DEVICE;
  /* hsdram1.Init */
  hsdram1.Init.SDBank = FMC_SDRAM_BANK1;
  hsdram1.Init.ColumnBitsNumber = FMC_SDRAM_COLUMN_BITS_NUM_8;
  hsdram1.Init.RowBitsNumber = FMC_SDRAM_ROW_BITS_NUM_13;
  hsdram1.Init.MemoryDataWidth = FMC_SDRAM_MEM_BUS_WIDTH_32;
  hsdram1.Init.InternalBankNumber = FMC_SDRAM_INTERN_BANKS_NUM_4;
  hsdram1.Init.CASLatency = FMC_SDRAM_CAS_LATENCY_2;
  hsdram1.Init.WriteProtection = FMC_SDRAM_WRITE_PROTECTION_DISABLE;
  hsdram1.Init.SDClockPeriod = FMC_SDRAM_CLOCK_PERIOD_2;
  hsdram1.Init.ReadBurst = FMC_SDRAM_RBURST_ENABLE;
  hsdram1.Init.ReadPipeDelay = FMC_SDRAM_RPIPE_DELAY_0;

  if (HAL_SDRAM_Init(&hsdram1, &SdramTiming) != HAL_OK)
  {
    Error_Handler( );
  }

  /** Perform the SDRAM2 memory initialization sequence
  */
  hsdram2.Instance = FMC_SDRAM_DEVICE;
  /* hsdram2.Init */
  hsdram2.Init.SDBank = FMC_SDRAM_BANK2;
  hsdram2.Init.ColumnBitsNumber = FMC_SDRAM_COLUMN_BITS_NUM_8;
  hsdram2.Init.RowBitsNumber = FMC_SDRAM_ROW_BITS_NUM_13;
  hsdram2.Init.MemoryDataWidth = FMC_SDRAM_MEM_BUS_WIDTH_32;
  hsdram2.Init.InternalBankNumber = FMC_SDRAM_INTERN_BANKS_NUM_4;
  hsdram2.Init.CASLatency = FMC_SDRAM_CAS_LATENCY_2;
  hsdram2.Init.WriteProtection = FMC_SDRAM_WRITE_PROTECTION_DISABLE;
  hsdram2.Init.SDClockPeriod = FMC_SDRAM_CLOCK_PERIOD_2;
  hsdram2.Init.ReadBurst = FMC_SDRAM_RBURST_ENABLE;
  hsdram2.Init.ReadPipeDelay = FMC_SDRAM_RPIPE_DELAY_0;

  if (HAL_SDRAM_Init(&hsdram2, &SdramTiming) != HAL_OK)
  {
    Error_Handler( );
  }

  /* USER CODE BEGIN FMC_Init 2 */

  Command.CommandMode            = FMC_SDRAM_CMD_CLK_ENABLE;
  Command.CommandTarget          = FMC_SDRAM_CMD_TARGET_BANK1_2;
  Command.AutoRefreshNumber      = 1;
  Command.ModeRegisterDefinition = 0;

  /* Send the command */
  if(HAL_SDRAM_SendCommand(&hsdram1, &Command, 1000) != HAL_OK)
  {
    Error_Handler( );
  }

  HAL_Delay(2);

  Command.CommandMode            = FMC_SDRAM_CMD_PALL;
  Command.CommandTarget          = FMC_SDRAM_CMD_TARGET_BANK1_2;
  Command.AutoRefreshNumber      = 1;
  Command.ModeRegisterDefinition = 0;

  /* Send the command */
  if(HAL_SDRAM_SendCommand(&hsdram1, &Command, 1000) != HAL_OK)
  {
    Error_Handler( );
  }

  Command.CommandMode            = FMC_SDRAM_CMD_AUTOREFRESH_MODE;
  Command.CommandTarget          = FMC_SDRAM_CMD_TARGET_BANK1_2;
  Command.AutoRefreshNumber      = 1;
  Command.ModeRegisterDefinition = 0;

  /* Send the command */
  if(HAL_SDRAM_SendCommand(&hsdram1, &Command, 1000) != HAL_OK)
  {
    Error_Handler( );
  }

  Command.CommandMode            = FMC_SDRAM_CMD_LOAD_MODE;
  Command.CommandTarget          = FMC_SDRAM_CMD_TARGET_BANK1_2;
  Command.AutoRefreshNumber      = 1;
  Command.ModeRegisterDefinition = 0x220;

  /* Send the command */
  if(HAL_SDRAM_SendCommand(&hsdram1, &Command, 1000) != HAL_OK)
  {
    Error_Handler( );
  }

  /* Send the command */
  if(HAL_SDRAM_ProgramRefreshRate(&hsdram1, 0x0603) != HAL_OK)
  {
    Error_Handler( );
  }
  HAL_Delay(2);

  uint32_t * const dst = (uint32_t *)&__tgfx_framebuffer_start;
  const uint32_t size = (&__tgfx_framebuffer_end - &__tgfx_framebuffer_start) * sizeof(uint32_t);

  memset(dst, 0, size);
  SCB_CleanDCache_by_Addr(dst, size);

  /* USER CODE END FMC_Init 2 */
}

static void MX_GPIO_Init(void)
{
  GPIO_InitTypeDef GPIO_InitStruct = {0};

  /* GPIO Ports Clock Enable */
  __HAL_RCC_GPIOI_CLK_ENABLE();
  __HAL_RCC_GPIOB_CLK_ENABLE();
  __HAL_RCC_GPIOK_CLK_ENABLE();
  __HAL_RCC_GPIOC_CLK_ENABLE();
  __HAL_RCC_GPIOE_CLK_ENABLE();
  __HAL_RCC_GPIOA_CLK_ENABLE();
  __HAL_RCC_GPIOH_CLK_ENABLE();
  __HAL_RCC_GPIOG_CLK_ENABLE();
  __HAL_RCC_GPIOD_CLK_ENABLE();
  __HAL_RCC_GPIOF_CLK_ENABLE();

  /*Configure GPIO pin Output Level */
  HAL_GPIO_WritePin(BL_CTRL_GPIO_Port, BL_CTRL_Pin, GPIO_PIN_RESET);

  /*Configure GPIO pin Output Level */
  HAL_GPIO_WritePin(BL_EN_GPIO_Port, BL_EN_Pin, GPIO_PIN_RESET);

  /*Configure GPIO pin Output Level */
  HAL_GPIO_WritePin(DSI_EN_GPIO_Port, DSI_EN_Pin, GPIO_PIN_RESET);

  /*Configure GPIO pin Output Level */
  HAL_GPIO_WritePin(SPI1_NSS_GPIO_Port, SPI1_NSS_Pin, GPIO_PIN_SET);

  /*Configure GPIO pin Output Level */
  HAL_GPIO_WritePin(FLEXIO_NRST_GPIO_Port, FLEXIO_NRST_Pin, GPIO_PIN_RESET);

  /*Configure GPIO pin Output Level */
  HAL_GPIO_WritePin(FLEXIO_SYNC_GPIO_Port, FLEXIO_SYNC_Pin, GPIO_PIN_RESET);

  /*Configure GPIO pin : BL_CTRL_Pin */
  GPIO_InitStruct.Pin = BL_CTRL_Pin;
  GPIO_InitStruct.Mode = GPIO_MODE_OUTPUT_PP;
  GPIO_InitStruct.Pull = GPIO_NOPULL;
  GPIO_InitStruct.Speed = GPIO_SPEED_FREQ_LOW;
  HAL_GPIO_Init(BL_CTRL_GPIO_Port, &GPIO_InitStruct);

  /*Configure GPIO pin : BL_EN_Pin */
  GPIO_InitStruct.Pin = BL_EN_Pin;
  GPIO_InitStruct.Mode = GPIO_MODE_OUTPUT_PP;
  GPIO_InitStruct.Pull = GPIO_NOPULL;
  GPIO_InitStruct.Speed = GPIO_SPEED_FREQ_LOW;
  HAL_GPIO_Init(BL_EN_GPIO_Port, &GPIO_InitStruct);

  /*Configure GPIO pin : DSI_EN_Pin */
  GPIO_InitStruct.Pin = DSI_EN_Pin;
  GPIO_InitStruct.Mode = GPIO_MODE_OUTPUT_PP;
  GPIO_InitStruct.Pull = GPIO_NOPULL;
  GPIO_InitStruct.Speed = GPIO_SPEED_FREQ_VERY_HIGH;
  HAL_GPIO_Init(DSI_EN_GPIO_Port, &GPIO_InitStruct);

  /*Configure GPIO pin : DSI_IRQ_Pin */
  GPIO_InitStruct.Pin = DSI_IRQ_Pin;
  GPIO_InitStruct.Mode = GPIO_MODE_IT_RISING;
  GPIO_InitStruct.Pull = GPIO_PULLDOWN;
  HAL_GPIO_Init(DSI_IRQ_GPIO_Port, &GPIO_InitStruct);

  /*Configure GPIO pin : FLEXIO_WAKE_Pin */
  GPIO_InitStruct.Pin = FLEXIO_WAKE_Pin;
  GPIO_InitStruct.Mode = GPIO_MODE_IT_RISING;
  GPIO_InitStruct.Pull = GPIO_NOPULL;
  HAL_GPIO_Init(FLEXIO_WAKE_GPIO_Port, &GPIO_InitStruct);

  /*Configure GPIO pin : FLEXIO_INT_Pin */
  GPIO_InitStruct.Pin = FLEXIO_INT_Pin;
  GPIO_InitStruct.Mode = GPIO_MODE_IT_RISING;
  GPIO_InitStruct.Pull = GPIO_PULLDOWN;
  HAL_GPIO_Init(FLEXIO_INT_GPIO_Port, &GPIO_InitStruct);

  /*Configure GPIO pin : SPI1_NSS_Pin */
  GPIO_InitStruct.Pin = SPI1_NSS_Pin;
  GPIO_InitStruct.Mode = GPIO_MODE_OUTPUT_PP;
  GPIO_InitStruct.Pull = GPIO_NOPULL;
  GPIO_InitStruct.Speed = GPIO_SPEED_FREQ_VERY_HIGH;
  HAL_GPIO_Init(SPI1_NSS_GPIO_Port, &GPIO_InitStruct);

  /*Configure GPIO pin : FLEXIO_NRST_Pin */
  GPIO_InitStruct.Pin = FLEXIO_NRST_Pin;
  GPIO_InitStruct.Mode = GPIO_MODE_OUTPUT_PP;
  GPIO_InitStruct.Pull = GPIO_NOPULL;
  GPIO_InitStruct.Speed = GPIO_SPEED_FREQ_LOW;
  HAL_GPIO_Init(FLEXIO_NRST_GPIO_Port, &GPIO_InitStruct);

  /*Configure GPIO pin : FLEXIO_SYNC_Pin */
  GPIO_InitStruct.Pin = FLEXIO_SYNC_Pin;
  GPIO_InitStruct.Mode = GPIO_MODE_OUTPUT_PP;
  GPIO_InitStruct.Pull = GPIO_NOPULL;
  GPIO_InitStruct.Speed = GPIO_SPEED_FREQ_VERY_HIGH;
  HAL_GPIO_Init(FLEXIO_SYNC_GPIO_Port, &GPIO_InitStruct);

}

void StartDefaultTask(void *argument)
{
  /* init code for USB_DEVICE */
  MX_USB_DEVICE_Init();
  for(;;)
  {
    osDelay(1);
  }
}

 /* MPU Configuration */

void MPU_Config(void)
{
  MPU_Region_InitTypeDef MPU_InitStruct = {0};

  /* Disables the MPU */
  HAL_MPU_Disable();

  /** Initializes and configures the Region and the memory to be protected
  */
  MPU_InitStruct.Enable = MPU_REGION_ENABLE;
  MPU_InitStruct.Number = MPU_REGION_NUMBER0;
  MPU_InitStruct.BaseAddress = 0xC0000000;
  MPU_InitStruct.Size = MPU_REGION_SIZE_64MB;
  MPU_InitStruct.SubRegionDisable = 0;
  MPU_InitStruct.TypeExtField = MPU_TEX_LEVEL0;
  MPU_InitStruct.AccessPermission = MPU_REGION_PRIV_RW;
  MPU_InitStruct.DisableExec = MPU_INSTRUCTION_ACCESS_DISABLE;
  MPU_InitStruct.IsShareable = MPU_ACCESS_NOT_SHAREABLE;
  MPU_InitStruct.IsCacheable = MPU_ACCESS_CACHEABLE;
  MPU_InitStruct.IsBufferable = MPU_ACCESS_NOT_BUFFERABLE;

  HAL_MPU_ConfigRegion(&MPU_InitStruct);

  MPU_InitStruct.Enable = MPU_REGION_ENABLE;
  MPU_InitStruct.Number = MPU_REGION_NUMBER0;
  MPU_InitStruct.BaseAddress = 0x90000000;
  MPU_InitStruct.Size = MPU_REGION_SIZE_64MB;
  MPU_InitStruct.SubRegionDisable = 0;
  MPU_InitStruct.TypeExtField = MPU_TEX_LEVEL0;
  MPU_InitStruct.AccessPermission = MPU_REGION_PRIV_RW;
  MPU_InitStruct.DisableExec = MPU_INSTRUCTION_ACCESS_DISABLE;
  MPU_InitStruct.IsShareable = MPU_ACCESS_NOT_SHAREABLE;
  MPU_InitStruct.IsCacheable = MPU_ACCESS_CACHEABLE;
  MPU_InitStruct.IsBufferable = MPU_ACCESS_NOT_BUFFERABLE;

  HAL_MPU_ConfigRegion(&MPU_InitStruct);
  /* Enables the MPU */
  HAL_MPU_Enable(MPU_PRIVILEGED_DEFAULT);

}

void HAL_TIM_PeriodElapsedCallback(TIM_HandleTypeDef *htim)
{
  if (htim->Instance == TIM17) {
    HAL_IncTick();
  }
}

void Error_Handler(void)
{
  __disable_irq();
  while (1)
  {
  }
}
